VERSION "dbc-export 1 2026.26.6.5"

NS_ :

BS_:

BU_: BMS CC CP EPBR GTW HVP ICR PCS VCBATT1 VCFRONT VCLEFT VCRIGHT VCSEC

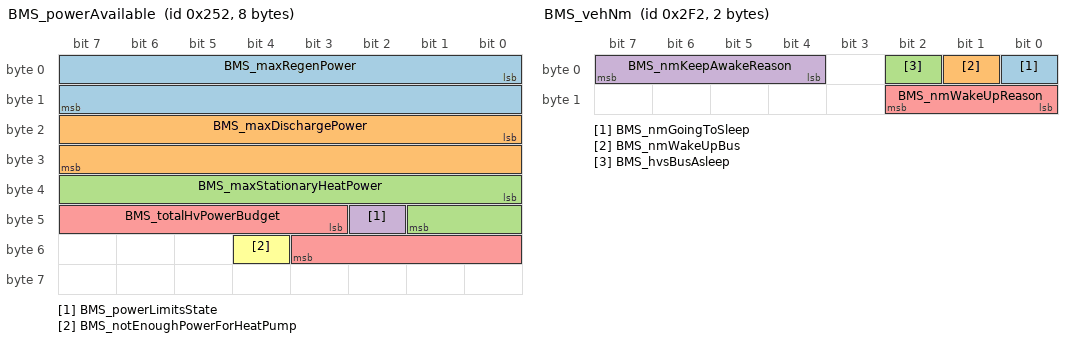
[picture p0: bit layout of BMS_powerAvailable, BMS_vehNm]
BO_ 594 BMS_powerAvailable: 8 BMS
 SG_ BMS_maxRegenPower : 0|16@1+ (0.01,0) [0|655.35] "kW" Vector__XXX
 SG_ BMS_maxDischargePower : 16|16@1+ (0.013,0) [0|850] "kW" Vector__XXX
 SG_ BMS_maxStationaryHeatPower : 32|10@1+ (0.01,0) [0|10.23] "kW" Vector__XXX
 SG_ BMS_powerLimitsState : 42|1@1+ (1,0) [0|1] "" Vector__XXX
 SG_ BMS_totalHvPowerBudget : 43|9@1+ (0.1,0) [0|51.1] "kW" Vector__XXX
 SG_ BMS_notEnoughPowerForHeatPump : 52|1@1+ (1,0) [0|1] "" Vector__XXX

BO_ 754 BMS_vehNm: 2 BMS
 SG_ BMS_nmGoingToSleep : 0|1@1+ (1,0) [0|1] "" Vector__XXX
 SG_ BMS_nmWakeUpBus : 1|1@1+ (1,0) [0|1] "" Vector__XXX
 SG_ BMS_hvsBusAsleep : 2|1@1+ (1,0) [0|1] "" Vector__XXX
 SG_ BMS_nmKeepAwakeReason : 4|4@1+ (1,0) [1|15] "" Vector__XXX
 SG_ BMS_nmWakeUpReason : 8|3@1+ (1,0) [0|7] "" Vector__XXX

BO_ 812 CC_logData: 8 CC
 SG_ CC_logIndex M : 0|8@1+ (1,0) [0|255] "" Vector__XXX
 SG_ CC_activeConnectorID m0 : 8|8@1+ (1,0) [0|255] "" Vector__XXX
 SG_ CC_temperature1 m0 : 16|8@1- (1,88) [-40|215] "DegC" Vector__XXX
 SG_ CC_temperature2 m0 : 24|8@1- (1,88) [-40|215] "DegC" Vector__XXX
 SG_ CC_temperature3 m0 : 32|8@1- (1,88) [-40|215] "DegC" Vector__XXX
 SG_ CC_contactor1Closed m0 : 40|2@1+ (1,0) [0|3] "" Vector__XXX
 SG_ CC_contactor2Closed m0 : 42|2@1+ (1,0) [0|3] "" Vector__XXX
 SG_ CC_temperature4 m0 : 44|8@1- (1,88) [-40|215] "DegC" Vector__XXX
 SG_ CC_conn1Current m1 : 8|8@1+ (0.5,0) [0|127] "A" Vector__XXX
 SG_ CC_conn2Current m2 : 8|8@1+ (0.5,0) [0|127] "A" Vector__XXX
 SG_ CC_conn3Current m3 : 8|8@1+ (0.5,0) [0|127] "A" Vector__XXX
 SG_ CC_conn4Current m4 : 8|8@1+ (0.5,0) [0|127] "A" Vector__XXX
 SG_ CC_lifetimei2t m10 : 32|32@1+ (0.1,0) [0|429496729.5] "A2h" Vector__XXX
 SG_ CC_lifetimeCtrCycles m11 : 8|28@1+ (1,0) [0|268435455] "" Vector__XXX
 SG_ CC_lifetimeCtrCyclesLoaded m11 : 36|28@1+ (1,0) [0|268435455] "" Vector__XXX
 SG_ CC_lifetimeAlertCount m12 : 8|28@1+ (1,0) [0|268435455] "" Vector__XXX
 SG_ CC_lifetimeThermalFoldbacks m12 : 36|28@1+ (1,0) [0|268435455] "" Vector__XXX
 SG_ CC_lifetimeAvgStartupTemp m13 : 36|28@1- (0.1,0) [-13421772.8|13421772.7] "degC" Vector__XXX

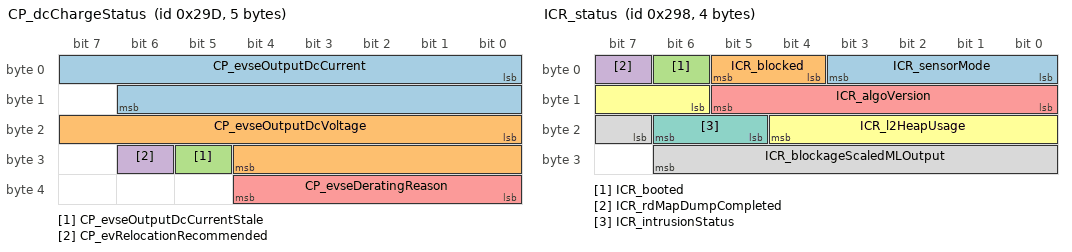
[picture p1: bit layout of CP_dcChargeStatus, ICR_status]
BO_ 669 CP_dcChargeStatus: 5 CP
 SG_ CP_evseOutputDcCurrent : 0|15@1- (0.125,0) [-2048|2047.875] "A" Vector__XXX
 SG_ CP_evseOutputDcVoltage : 16|13@1+ (0.07324219,0) [0|599.92675822] "V" Vector__XXX
 SG_ CP_evseOutputDcCurrentStale : 29|1@1+ (1,0) [0|1] "" Vector__XXX
 SG_ CP_evRelocationRecommended : 30|1@1+ (1,0) [0|1] "" Vector__XXX
 SG_ CP_evseDeratingReason : 32|5@1+ (1,0) [0|31] "" Vector__XXX

BO_ 1885 CP_loggingFast: 8 CP
 SG_ CP_loggingFastSelect M : 0|4@1+ (1,0) [0|15] "" Vector__XXX
 SG_ CP_inductiveSensor_raw m0 : 4|28@1+ (1,0) [0|268435455] "" Vector__XXX
 SG_ CP_doorOpenActuationTime m0 : 32|14@1+ (1,0) [0|16383] "ms" Vector__XXX
 SG_ CP_doorCloseActuationTime m0 : 46|14@1+ (1,0) [0|16383] "ms" Vector__XXX
 SG_ CP_chargeCableSecured m0 : 60|1@1+ (1,0) [0|1] "" Vector__XXX
 SG_ CP_chargeCablePresent m0 : 61|1@1+ (1,0) [0|1] "" Vector__XXX
 SG_ CP_latchCheckAvailable m0 : 62|1@1+ (1,0) [0|1] "" Vector__XXX
 SG_ CP_UHF_controlState m2 : 4|4@1+ (1,0) [0|15] "" Vector__XXX
 SG_ CP_proximityV m2 : 8|16@1+ (0.0001,0) [0|6.5535] "V" Vector__XXX
 SG_ CP_proximityV_GBCC1 m2 : 24|14@1+ (0.001,0) [0|13.3] "V" Vector__XXX
 SG_ CP_proximityV_GBCC2 m2 : 38|14@1+ (0.001,0) [0|13.3] "V" Vector__XXX
 SG_ CP_doorPot m2 : 52|12@1+ (0.025,0) [0|100] "%" Vector__XXX
 SG_ CP_doorPresenceSensorV m3 : 4|12@1+ (0.001221,0) [0|4.999995] "V" Vector__XXX
 SG_ CP_doorOpenRequest m3 : 16|4@1+ (1,0) [0|15] "" Vector__XXX
 SG_ CP_doorOpenEndOfDriveReason m3 : 20|3@1+ (1,0) [0|7] "" Vector__XXX
 SG_ CP_coverClosed m3 : 23|1@1+ (1,0) [0|1] "" Vector__XXX
 SG_ CP_doorCloseEndOfDriveReason m3 : 24|3@1+ (1,0) [0|7] "" Vector__XXX
 SG_ CP_doorCloseRequest m3 : 27|5@1+ (1,0) [0|31] "" Vector__XXX
 SG_ CP_latchDisengagingTime m3 : 32|10@1+ (1,0) [0|1023] "ms" Vector__XXX
 SG_ CP_latchEngagingTime m3 : 42|10@1+ (1,0) [0|1023] "ms" Vector__XXX
 SG_ CP_latchDisengagingStopReason m3 : 52|3@1+ (1,0) [0|7] "" Vector__XXX
 SG_ CP_latchEngagingStopReason m3 : 55|3@1+ (1,0) [0|7] "" Vector__XXX
 SG_ CP_pilotUnlatchRequestActive m3 : 58|1@1+ (1,0) [0|1] "" Vector__XXX
 SG_ CP_doorIdDetectionState m3 : 59|2@1+ (1,0) [1|3] "" Vector__XXX
 SG_ CP_doorIdDetectedBin m3 : 61|2@1+ (1,0) [0|3] "" Vector__XXX
 SG_ CP_semiV2LatchNonLinear m3 : 63|1@1+ (1,0) [0|1] "" Vector__XXX

BO_ 989 CP_loggingSlow: 8 CP
 SG_ CP_loggingSlowSelect M : 0|4@1+ (1,0) [0|15] "" Vector__XXX
 SG_ CP_UHF_chipState m3 : 4|3@1+ (1,0) [0|7] "" Vector__XXX
 SG_ CP_UHF_rssi m3 : 8|8@1+ (1,0) [0|255] "" Vector__XXX
 SG_ CP_UHF_rxOverflow m3 : 16|1@1+ (1,0) [0|1] "" Vector__XXX
 SG_ CP_UHF_rxNumBytes m3 : 17|8@1+ (1,0) [0|255] "" Vector__XXX
 SG_ CP_UHF_selfTestRssi m3 : 25|8@1+ (1,0) [0|255] "" Vector__XXX
 SG_ CP_latchI m3 : 33|12@1+ (0.0025,0) [0|10.2375] "A" Vector__XXX
 SG_ CP_inlet1HarnessIdState m3 : 45|2@1+ (1,0) [1|3] "" Vector__XXX
 SG_ CP_inlet1HarnessIdValue m3 : 47|3@1+ (1,0) [0|7] "" Vector__XXX
 SG_ CP_inlet2HarnessIdState m3 : 50|2@1+ (1,0) [1|3] "" Vector__XXX
 SG_ CP_inlet2HarnessIdValue m3 : 52|3@1+ (1,0) [0|7] "" Vector__XXX
 SG_ CP_inletHeaterState m3 : 55|2@1+ (1,0) [0|3] "" Vector__XXX
 SG_ CP_inletHeaterDuty m3 : 57|7@1+ (1,0) [0|100] "%" Vector__XXX
 SG_ CP_5vSwV m4 : 4|8@1+ (0.02745098,0) [0|6.9999999] "V" Vector__XXX
 SG_ CP_boardTemperature m4 : 12|8@1+ (1.29411768913,-50) [-50|280] "C" Vector__XXX
 SG_ CP_refVoltage m4 : 20|8@1+ (0.0070588234812,0) [0|1.79999998771] "V" Vector__XXX
 SG_ CP_doorId_intervalMin10s m4 : 28|8@1+ (0.0196078438312,0) [0|5] "V" Vector__XXX
 SG_ CP_doorId_intervalMax10s m4 : 36|8@1+ (0.0196078438312,0) [0|5] "V" Vector__XXX
 SG_ CP_wakeOnPushCounter m4 : 60|3@1+ (1,0) [0|7] "" Vector__XXX
 SG_ CP_doorPushLockoutActive m4 : 63|1@1+ (1,0) [0|1] "" Vector__XXX
 SG_ CP_nvm_dataValid m5 : 4|1@1+ (1,0) [0|1] "" Vector__XXX
 SG_ CP_nvm_doorOpenCycles m5 : 5|16@1+ (1,0) [0|65535] "" Vector__XXX
 SG_ CP_nvm_doorCloseCycles m5 : 21|16@1+ (1,0) [0|65535] "" Vector__XXX
 SG_ CP_nvm_doorOpen m5 : 37|1@1+ (1,0) [0|1] "" Vector__XXX
 SG_ CP_nvm_doorPresent m5 : 38|1@1+ (1,0) [0|1] "" Vector__XXX
 SG_ CP_nvm_doorPresentValid m5 : 39|1@1+ (1,0) [0|1] "" Vector__XXX
 SG_ CP_nvm_badPilotDiodeDetected m5 : 40|1@1+ (1,0) [0|1] "" Vector__XXX
 SG_ CP_nvm_pilotDiodeFaultCount m5 : 41|3@1+ (1,0) [0|7] "" Vector__XXX
 SG_ CP_doorOpenLimiterMaxCount m5 : 44|4@1+ (1,0) [0|15] "counts" Vector__XXX
 SG_ CP_doorOpenLimiterMaxRequestType m5 : 48|4@1+ (1,0) [0|15] "" Vector__XXX
 SG_ CP_doorCloseLimiterMaxCount m5 : 52|4@1+ (1,0) [0|15] "counts" Vector__XXX
 SG_ CP_doorCloseLimiterMaxRequestTyp m5 : 56|5@1+ (1,0) [0|31] "" Vector__XXX
 SG_ CP_proximityWakeCounter m5 : 61|3@1+ (1,0) [0|7] "" Vector__XXX

BO_ 893 CP_thermalStatus: 8 CP
 SG_ CP_thermalStatusSelect M : 0|1@1+ (1,0) [0|1] "" Vector__XXX
 SG_ CP_pinTemperature1 m1 : 8|8@1+ (0.8039216,-55) [-55|149.99] "C" Vector__XXX
 SG_ CP_pinTemperature2 m1 : 16|8@1+ (0.8039216,-55) [-55|149.99] "C" Vector__XXX
 SG_ CP_pinTemperature3 m1 : 24|8@1+ (0.8039216,-55) [-55|149.99] "C" Vector__XXX
 SG_ CP_pinTemperature4 m1 : 32|8@1+ (0.8039216,-55) [-55|149.99] "C" Vector__XXX
 SG_ CP_pinTemp4Velocity m1 : 40|10@1- (0.15748,0) [-80.47228|80.3148] "C/min" Vector__XXX

BO_ 2024 EPBR_info: 8 EPBR
 SG_ EPBR_infoIndex M : 0|8@1+ (1,0) [0|255] "" Vector__XXX
 SG_ EPBR_infoBuildType m10 : 8|3@1+ (1,0) [0|7] "" Vector__XXX
 SG_ EPBR_infoBuildConfigId m10 : 16|16@1+ (1,0) [0|65535] "" Vector__XXX
 SG_ EPBR_infoHardwareId m10 : 32|16@1+ (1,0) [0|65535] "" Vector__XXX
 SG_ EPBR_infoComponentId m10 : 48|16@1+ (1,0) [0|65535] "" Vector__XXX
 SG_ EPBR_infoPcbaId m11 : 8|8@1+ (1,0) [0|255] "" Vector__XXX
 SG_ EPBR_infoAssemblyId m11 : 16|8@1+ (1,0) [0|254] "" Vector__XXX
 SG_ EPBR_infoUsageId m11 : 24|16@1+ (1,0) [0|65535] "" Vector__XXX
 SG_ EPBR_infoSubUsageId m11 : 40|16@1+ (1,0) [0|65535] "" Vector__XXX
 SG_ EPBR_infoAppCrc m13 : 8|32@1+ (1,0) [0|4294967295] "" Vector__XXX
 SG_ EPBR_infoAppGitHash m17 : 8|56@1+ (1,0) [0|7.20575940379e+16] "" Vector__XXX
 SG_ EPBR_infoBootGitHash m18 : 8|56@1+ (1,0) [0|7.20575940379e+16] "" Vector__XXX
 SG_ EPBR_infoPlatformType m19 : 8|8@1+ (1,0) [0|255] "" Vector__XXX
 SG_ EPBR_infoBootUdsProtoVersion m20 : 8|16@1+ (1,0) [0|65535] "" Vector__XXX
 SG_ EPBR_infoBootCrc m20 : 24|32@1+ (1,0) [0|4294967295] "" Vector__XXX

BO_ 1914 HVP_log1hz: 8 HVP
 SG_ HVP_log1HzIndex M : 0|3@1+ (1,0) [0|7] "" Vector__XXX
 SG_ HVP_bmbAsicType m0 : 3|2@1+ (1,0) [0|3] "" Vector__XXX
 SG_ HVP_shuntCurrentAuxLog m0 : 8|24@1- (0.001,0) [-8388.607|8388.607] "A" Vector__XXX
 SG_ HVP_pyroSquibResistance m0 : 32|16@1+ (0.001,0) [0|65.534] "Ohm" Vector__XXX
 SG_ HVP_shuntAsicChipXCoordinate m0 : 48|8@1+ (1,0) [0|255] "" Vector__XXX
 SG_ HVP_shuntAsicChipYCoordinate m0 : 56|8@1+ (1,0) [0|255] "" Vector__XXX
 SG_ HVP_hvilCalType m1 : 3|2@1+ (1,0) [0|3] "" Vector__XXX
 SG_ HVP_gpioPcsDcdcPwmEnable m1 : 5|1@1+ (1,0) [0|1] "" Vector__XXX
 SG_ HVP_gpioPcsChargePwmEnable m1 : 6|1@1+ (1,0) [0|1] "" Vector__XXX
 SG_ HVP_gpioPcsEnable m1 : 7|1@1+ (1,0) [0|1] "" Vector__XXX
 SG_ HVP_shuntAsicChipWaferNumber m1 : 8|8@1+ (1,0) [0|255] "" Vector__XXX
 SG_ HVP_energyReserveMin m1 : 16|16@1- (0.001,0) [-32.768|32.767] "V" Vector__XXX
 SG_ HVP_energyReserveMax m1 : 32|16@1- (0.001,0) [-32.768|32.767] "V" Vector__XXX
 SG_ HVP_energyReserveAvg m1 : 48|16@1- (0.001,0) [-32.768|32.767] "V" Vector__XXX

BO_ 664 ICR_status: 4 ICR
 SG_ ICR_sensorMode : 0|4@1+ (1,0) [0|15] "" Vector__XXX
 SG_ ICR_blocked : 4|2@1+ (1,0) [1|3] "" Vector__XXX
 SG_ ICR_booted : 6|1@1+ (1,0) [0|1] "" Vector__XXX
 SG_ ICR_rdMapDumpCompleted : 7|1@1+ (1,0) [0|1] "" Vector__XXX
 SG_ ICR_algoVersion : 8|6@1+ (1,0) [0|63] "" Vector__XXX
 SG_ ICR_l2HeapUsage : 14|7@1+ (1,0) [0|127] "PCT" Vector__XXX
 SG_ ICR_intrusionStatus : 21|2@1+ (1,0) [0|3] "" Vector__XXX
 SG_ ICR_blockageScaledMLOutput : 23|8@1+ (0.004,0) [0|1.02] "points" Vector__XXX

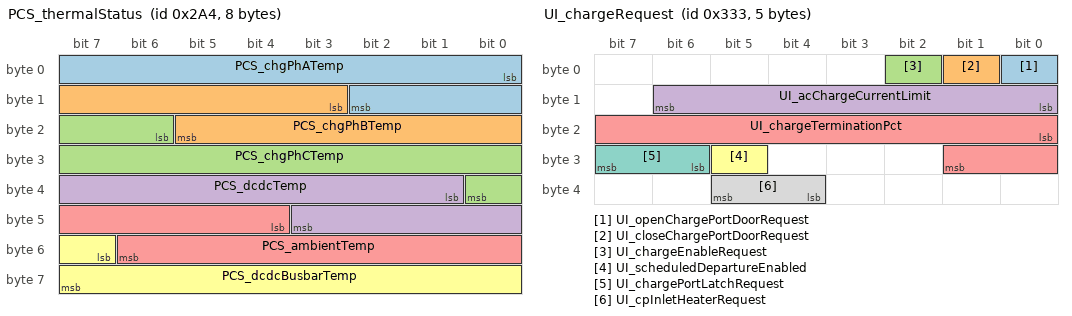
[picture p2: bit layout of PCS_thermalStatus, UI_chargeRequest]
BO_ 676 PCS_thermalStatus: 8 PCS
 SG_ PCS_chgPhATemp : 0|11@1- (0.1,40) [-62.4|142.3] "C" Vector__XXX
 SG_ PCS_chgPhBTemp : 11|11@1- (0.1,40) [-62.4|142.3] "C" Vector__XXX
 SG_ PCS_chgPhCTemp : 22|11@1- (0.1,40) [-62.4|142.3] "C" Vector__XXX
 SG_ PCS_dcdcTemp : 33|11@1- (0.1,40) [-62.4|142.3] "C" Vector__XXX
 SG_ PCS_ambientTemp : 44|11@1- (0.1,40) [-62.4|142.3] "C" Vector__XXX
 SG_ PCS_dcdcBusbarTemp : 55|9@1+ (0.2935421,0) [0|149.706471] "C" Vector__XXX

BO_ 819 UI_chargeRequest: 5 GTW
 SG_ UI_openChargePortDoorRequest : 0|1@1+ (1,0) [0|1] "" Vector__XXX
 SG_ UI_closeChargePortDoorRequest : 1|1@1+ (1,0) [0|1] "" Vector__XXX
 SG_ UI_chargeEnableRequest : 2|1@1+ (1,0) [0|1] "" Vector__XXX
 SG_ UI_acChargeCurrentLimit : 8|7@1+ (1,0) [0|126] "A" Vector__XXX
 SG_ UI_chargeTerminationPct : 16|10@1+ (0.1,0) [5|100] "%" Vector__XXX
 SG_ UI_scheduledDepartureEnabled : 29|1@1+ (1,0) [0|1] "" Vector__XXX
 SG_ UI_chargePortLatchRequest : 30|2@1+ (1,0) [0|3] "" Vector__XXX
 SG_ UI_cpInletHeaterRequest : 36|2@1+ (1,0) [0|3] "" Vector__XXX

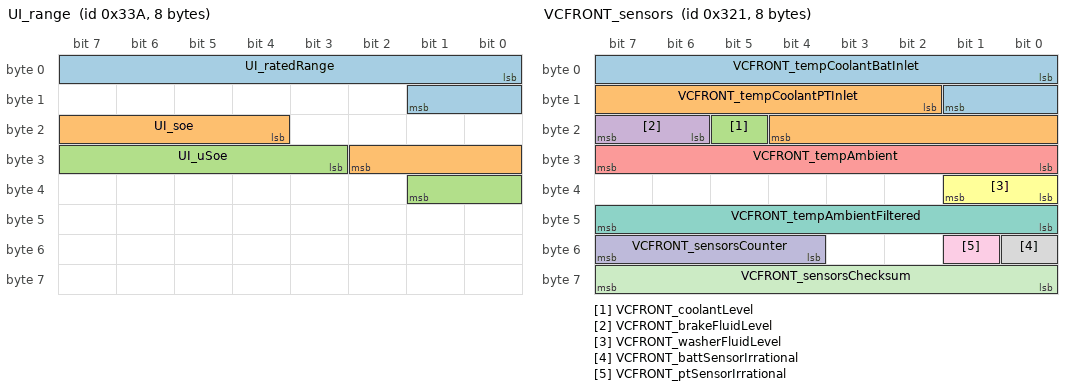
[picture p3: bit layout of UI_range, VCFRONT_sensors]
BO_ 826 UI_range: 8 GTW
 SG_ UI_ratedRange : 0|10@1+ (1,0) [0|1023] "mi" Vector__XXX
 SG_ UI_soe : 20|7@1+ (1,0) [0|127] "%" Vector__XXX
 SG_ UI_uSoe : 27|7@1+ (1,0) [0|127] "%" Vector__XXX

BO_ 1119 VCBATT1_LVSelfTests: 8 VCBATT1
 SG_ VCBATT1_LVSelfTestsChecksum : 0|8@1+ (1,0) [0|255] "" Vector__XXX
 SG_ VCBATT1_LVSelfTestsCounter : 8|4@1+ (1,0) [0|15] "" Vector__XXX
 SG_ VCBATT1_LVSelfTestsIndex M : 12|1@1+ (1,0) [0|1] "" Vector__XXX
 SG_ VCBATT1_lvProtectionSelfTestsEna m1 : 13|1@1+ (1,0) [0|1] "" Vector__XXX
 SG_ VCBATT1_startBattDomainOvercurre m1 : 14|1@1+ (1,0) [0|1] "" Vector__XXX
 SG_ VCBATT1_startBattDomainOvervolta m1 : 15|1@1+ (1,0) [0|1] "" Vector__XXX
 SG_ VCBATT1_startBattDomainUndervolt m1 : 16|1@1+ (1,0) [0|1] "" Vector__XXX
 SG_ VCBATT1_startDualPowerLoadsSelfT m1 : 17|1@1+ (1,0) [0|1] "" Vector__XXX
 SG_ VCBATT1_startVCBattBridgeEFuseAS m1 : 18|1@1+ (1,0) [0|1] "" Vector__XXX
 SG_ VCBATT1_startPCSOVShutdownSelfTe m1 : 19|1@1+ (1,0) [0|1] "" Vector__XXX
 SG_ VCBATT1_startPCSDomainOvervoltag m1 : 20|1@1+ (1,0) [0|1] "" Vector__XXX
 SG_ VCBATT1_startBattDomainUnde_0001 m1 : 21|1@1+ (1,0) [0|1] "" Vector__XXX
 SG_ VCBATT1_startPCSDomainUndervolta m1 : 22|1@1+ (1,0) [0|1] "" Vector__XXX
 SG_ VCBATT1_startVCFrontBridgeEFuseA m1 : 23|1@1+ (1,0) [0|1] "" Vector__XXX
 SG_ VCBATT1_battDomainOvercurrentSel m1 : 24|2@1+ (1,0) [0|3] "" Vector__XXX
 SG_ VCBATT1_battDomainOvercurre_0001 m1 : 26|3@1+ (1,0) [0|7] "" Vector__XXX
 SG_ VCBATT1_battDomainOvervoltageSel m1 : 29|2@1+ (1,0) [0|3] "" Vector__XXX
 SG_ VCBATT1_battDomainOvervolta_0001 m1 : 32|3@1+ (1,0) [0|7] "" Vector__XXX
 SG_ VCBATT1_battDomainUndervoltageSe m1 : 35|2@1+ (1,0) [0|3] "" Vector__XXX
 SG_ VCBATT1_battDomainUndervolt_0001 m1 : 37|3@1+ (1,0) [0|7] "" Vector__XXX
 SG_ VCBATT1_dualPowerLoadsSelfTestRe m1 : 40|2@1+ (1,0) [0|3] "" Vector__XXX
 SG_ VCBATT1_dualPowerLoadsSelfTestSt m1 : 42|3@1+ (1,0) [0|7] "" Vector__XXX
 SG_ VCBATT1_vcbattBridgeEFuseASICSel m1 : 45|2@1+ (1,0) [0|3] "" Vector__XXX
 SG_ VCBATT1_vcbattBridgeEFuseAS_0001 m1 : 48|3@1+ (1,0) [0|7] "" Vector__XXX
 SG_ VCBATT1_uvProtectionState m1 : 51|4@1+ (1,0) [0|15] "" Vector__XXX
 SG_ VCBATT1_undervoltageSelfTestFaul m1 : 55|1@1+ (1,0) [0|1] "" Vector__XXX
 SG_ VC_selfTestsRunningMode m1 : 56|3@1+ (1,0) [0|7] "" Vector__XXX

BO_ 801 VCFRONT_sensors: 8 VCFRONT
 SG_ VCFRONT_tempCoolantBatInlet : 0|10@1+ (0.125,-40) [-40|85] "degC" Vector__XXX
 SG_ VCFRONT_tempCoolantPTInlet : 10|11@1+ (0.125,-40) [-40|200] "degC" Vector__XXX
 SG_ VCFRONT_coolantLevel : 21|1@1+ (1,0) [0|1] "" Vector__XXX
 SG_ VCFRONT_brakeFluidLevel : 22|2@1+ (1,0) [1|3] "" Vector__XXX
 SG_ VCFRONT_tempAmbient : 24|8@1+ (0.5,-40) [-39.5|80] "degC" Vector__XXX
 SG_ VCFRONT_washerFluidLevel : 32|2@1+ (1,0) [1|3] "" Vector__XXX
 SG_ VCFRONT_tempAmbientFiltered : 40|8@1+ (0.5,-40) [-39.5|80] "degC" Vector__XXX
 SG_ VCFRONT_battSensorIrrational : 48|1@1+ (1,0) [0|1] "" Vector__XXX
 SG_ VCFRONT_ptSensorIrrational : 49|1@1+ (1,0) [0|1] "" Vector__XXX
 SG_ VCFRONT_sensorsCounter : 52|4@1+ (1,0) [0|15] "" Vector__XXX
 SG_ VCFRONT_sensorsChecksum : 56|8@1+ (1,0) [0|255] "" Vector__XXX

BO_ 1349 VCFRONT_systemStatus: 8 VCFRONT
 SG_ VCFRONT_systemStatusMuxIndex M : 0|2@1+ (1,0) [0|3] "" Vector__XXX
 SG_ VCFRONT_systemStatusCounter : 52|4@1+ (1,0) [0|15] "" Vector__XXX
 SG_ VCFRONT_systemStatusChecksum : 56|8@1+ (1,0) [0|255] "" Vector__XXX
 SG_ VCFRONT_loadShedReason m1 : 3|9@1+ (1,0) [0|511] "" Vector__XXX
 SG_ VCFRONT_VCRightEFuseLoadShedStag m1 : 12|5@1+ (1,0) [0|31] "" Vector__XXX
 SG_ VCFRONT_VCLeftEFuseLoadShedStage m1 : 20|5@1+ (1,0) [0|31] "" Vector__XXX
 SG_ VCFRONT_DCDCSaturationLoadShedSt m1 : 28|5@1+ (1,0) [0|31] "" Vector__XXX
 SG_ VCFRONT_vehicleLoadShedStage m1 : 36|2@1+ (1,0) [0|3] "" Vector__XXX
 SG_ VCFRONT_HVFaultVehicleLoadShedRe m1 : 38|1@1+ (1,0) [0|1] "" Vector__XXX
 SG_ VCFRONT_postCrashVehicleLoadShed m1 : 39|1@1+ (1,0) [0|1] "" Vector__XXX
 SG_ VCFRONT_HVFaultVehicleLoadShedAc m1 : 40|1@1+ (1,0) [0|1] "" Vector__XXX
 SG_ VCFRONT_factoryVehicleLoadShedAc m1 : 41|1@1+ (1,0) [0|1] "" Vector__XXX
 SG_ VCFRONT_anyVehicleLoadShedActive m1 : 42|1@1+ (1,0) [0|1] "" Vector__XXX
 SG_ VCFRONT_DIVehLoadShedActive m1 : 43|1@1+ (1,0) [0|1] "" Vector__XXX
 SG_ VCFRONT_HVFaultLoadShedStateDBG m1 : 44|2@1+ (1,0) [0|3] "" Vector__XXX
 SG_ VCFRONT_LVUnhealthyVehicleLoadSh m1 : 46|1@1+ (1,0) [0|1] "" Vector__XXX
 SG_ VCFRONT_loadShedStsCondenserFan m2 : 3|1@1+ (1,0) [0|1] "" Vector__XXX
 SG_ VCFRONT_loadShedStsPTPump m2 : 6|1@1+ (1,0) [0|1] "" Vector__XXX
 SG_ VCFRONT_loadShedMCUAudio m2 : 10|1@1+ (1,0) [0|1] "" Vector__XXX
 SG_ VCFRONT_loadShedHVDownTriggerDBG m2 : 11|1@1+ (1,0) [0|1] "" Vector__XXX
 SG_ VCFRONT_loadShedPCSSatTriggerDBG m2 : 12|1@1+ (1,0) [0|1] "" Vector__XXX
 SG_ VCFRONT_loadShedStsBatteryPump m2 : 13|1@1+ (1,0) [0|1] "" Vector__XXX
 SG_ VCFRONT_loadShedStsAPGlassHeater m2 : 14|1@1+ (1,0) [0|1] "" Vector__XXX
 SG_ VCFRONT_loadShedStsMCUGraphics m2 : 15|1@1+ (1,0) [0|1] "" Vector__XXX
 SG_ VCFRONT_IBSCurrentRMS_loadShed m2 : 16|7@1+ (0.05,0) [0|6.35] "A" Vector__XXX
 SG_ VCFRONT_loadShedAhLeakyBktCntDBG m2 : 23|9@1+ (0.001,0) [0|0.511] "Ah" Vector__XXX
 SG_ VCFRONT_loadShedPcs m2 : 33|1@1+ (1,0) [0|1] "" Vector__XXX
 SG_ VCFRONT_loadShedGTWDownstrmRails m2 : 35|1@1+ (1,0) [0|1] "" Vector__XXX
 SG_ VCFRONT_loadShedPCSMIATriggerDBG m2 : 36|1@1+ (1,0) [0|1] "" Vector__XXX
 SG_ VCFRONT_loadShedTAS m2 : 37|1@1+ (1,0) [0|1] "" Vector__XXX
 SG_ VCFRONT_loadShedBackStopBktCntDB m2 : 38|5@1+ (0.05,0) [0|1.55] "Ah" Vector__XXX
 SG_ VCFRONT_loadShedPCSLeakyBktCtDBG m2 : 44|6@1+ (100,0) [0|6300] "mV" Vector__XXX
 SG_ VCFRONT_loadShedUI m2 : 50|1@1+ (1,0) [0|1] "" Vector__XXX
 SG_ VCFRONT_loadShedAutoPilot m2 : 51|1@1+ (1,0) [0|1] "" Vector__XXX

BO_ 929 VCFRONT_vehicleStatus: 8 VCFRONT
 SG_ VCFRONT_vehicleStatusMuxIndex M : 0|1@1+ (1,0) [0|1] "" Vector__XXX
 SG_ VCFRONT_vehicleStatusCounter : 52|4@1+ (1,0) [0|15] "" Vector__XXX
 SG_ VCFRONT_vehicleStatusChecksum : 56|8@1+ (1,0) [0|255] "" Vector__XXX
 SG_ VCFRONT_preconditionRequest m0 : 1|1@1+ (1,0) [0|1] "" Vector__XXX
 SG_ VCFRONT_APGlassHeaterState m0 : 2|3@1+ (1,0) [1|7] "" Vector__XXX
 SG_ VCFRONT_thermalSystemType m0 : 5|1@1+ (1,0) [0|1] "" Vector__XXX
 SG_ VCFRONT_standbySupplySupported m0 : 6|1@1+ (1,0) [0|1] "" Vector__XXX
 SG_ VCFRONT_driverPresent m0 : 7|1@1+ (1,0) [0|1] "" Vector__XXX
 SG_ VCFRONT_passengerPresent m0 : 8|1@1+ (1,0) [0|1] "" Vector__XXX
 SG_ VCFRONT_accPlusAvailable m0 : 9|1@1+ (1,0) [0|1] "" Vector__XXX
 SG_ VCFRONT_diPowerOnState m0 : 10|3@1+ (1,0) [0|7] "" Vector__XXX
 SG_ VCFRONT_12vStatusForDrive m0 : 14|2@1+ (1,0) [0|3] "" Vector__XXX
 SG_ VCFRONT_dcr12VMilliOhms m0 : 16|8@1+ (1,0) [0|255] "mOhm" Vector__XXX
 SG_ VC_userPresenceState m0 : 24|2@1+ (1,0) [0|3] "" Vector__XXX
 SG_ VCFRONT_factoryLimitsOverrideOk m0 : 27|1@1+ (1,0) [0|1] "" Vector__XXX
 SG_ VCFRONT_ota12VSupportRequest m0 : 29|1@1+ (1,0) [0|1] "" Vector__XXX
 SG_ VCFRONT_driverBuckleStatus m0 : 30|1@1+ (1,0) [0|1] "" Vector__XXX
 SG_ VCFRONT_driverDoorStatus m0 : 31|1@1+ (1,0) [0|1] "" Vector__XXX
 SG_ VCFRONT_driverUnbuckled m0 : 32|2@1+ (1,0) [0|3] "" Vector__XXX
 SG_ VCFRONT_passengerUnbuckled m0 : 34|2@1+ (1,0) [0|3] "" Vector__XXX
 SG_ VCFRONT_2RowLeftUnbuckled m0 : 36|2@1+ (1,0) [0|3] "" Vector__XXX
 SG_ VCFRONT_2RowCenterUnbuckled m0 : 38|2@1+ (1,0) [0|3] "" Vector__XXX
 SG_ VCFRONT_2RowRightUnbuckled m0 : 40|2@1+ (1,0) [0|3] "" Vector__XXX
 SG_ VCFRONT_pcsEFuseVoltage m0 : 42|10@1+ (0.1,0) [0|102.2] "V" Vector__XXX
 SG_ VCFRONT_bmsHvChargeEnable m1 : 1|1@1+ (1,0) [0|1] "" Vector__XXX
 SG_ VCFRONT_3RowLeftUnbuckled m1 : 2|2@1+ (1,0) [0|3] "" Vector__XXX
 SG_ VCFRONT_3RowRightUnbuckled m1 : 4|2@1+ (1,0) [0|3] "" Vector__XXX
 SG_ VCFRONT_maxBattHeatRejection m1 : 6|10@1+ (30,0) [0|30690] "W" Vector__XXX
 SG_ VCFRONT_hvacReqBattCoolOutTemp m1 : 16|9@1+ (0.1,40) [40|91.1] "degC" Vector__XXX
 SG_ VCFRONT_PCSCurrent m1 : 25|13@1- (0.1,0) [-409.6|409.5] "A" Vector__XXX
 SG_ VCFRONT_refSystemNominal m1 : 38|1@1+ (1,0) [0|1] "" Vector__XXX
 SG_ VCFRONT_driverEnteredCabinEstima m1 : 39|1@1+ (1,0) [0|1] "" Vector__XXX
 SG_ VCFRONT_anySWEFuseActive m1 : 40|1@1+ (1,0) [0|1] "" Vector__XXX
 SG_ VCFRONT_hpBattHeatingPowerTrgt m1 : 41|7@1+ (100,0) [0|10000] "W" Vector__XXX

BO_ 258 VCLEFT_doorStatus: 8 VCLEFT
 SG_ VCLEFT_doorClosureStatusFront : 0|4@1+ (1,0) [1|15] "" Vector__XXX
 SG_ VCLEFT_doorClosureStatusRear : 4|4@1+ (1,0) [1|15] "" Vector__XXX
 SG_ VCLEFT_frontLatchSwitch : 8|1@1+ (1,0) [0|1] "" Vector__XXX
 SG_ VCLEFT_rearLatchSwitch : 9|1@1+ (1,0) [0|1] "" Vector__XXX
 SG_ VCLEFT_frontHandlePulled : 10|1@1+ (1,0) [0|1] "" Vector__XXX
 SG_ VCLEFT_rearHandlePulled : 11|1@1+ (1,0) [0|1] "" Vector__XXX
 SG_ VCLEFT_frontRelActuatorSwitch : 12|1@1+ (1,0) [0|1] "" Vector__XXX
 SG_ VCLEFT_rearRelActuatorSwitch : 13|1@1+ (1,0) [0|1] "" Vector__XXX
 SG_ VCLEFT_frontLatchStatus : 14|4@1+ (1,0) [1|15] "" Vector__XXX
 SG_ VCLEFT_rearLatchStatus : 18|4@1+ (1,0) [1|15] "" Vector__XXX
 SG_ VCLEFT_lastDoorReqSourceFront : 22|3@1+ (1,0) [0|7] "" Vector__XXX
 SG_ VCLEFT_lastDoorReqSourceRear : 25|3@1+ (1,0) [0|7] "" Vector__XXX
 SG_ VCLEFT_frontIntSwitchFaulted : 28|1@1+ (1,0) [0|1] "" Vector__XXX
 SG_ VCLEFT_rearIntSwitchFaulted : 29|1@1+ (1,0) [0|1] "" Vector__XXX
 SG_ VCLEFT_frontIntSwitchPressed : 31|1@1+ (1,0) [0|1] "" Vector__XXX
 SG_ VCLEFT_rearIntSwitchPressed : 32|1@1+ (1,0) [0|1] "" Vector__XXX
 SG_ VCLEFT_mirrorTiltXPosition : 33|8@1+ (0.02,0) [0|5] "V" Vector__XXX
 SG_ VCLEFT_mirrorTiltYPosition : 41|8@1+ (0.02,0) [0|5] "V" Vector__XXX
 SG_ VCLEFT_mirrorState : 49|3@1+ (1,0) [0|7] "" Vector__XXX
 SG_ VCLEFT_mirrorFoldState : 52|3@1+ (1,0) [0|7] "" Vector__XXX
 SG_ VCLEFT_mirrorRecallState : 55|3@1+ (1,0) [0|7] "" Vector__XXX
 SG_ VCLEFT_mirrorHeatState : 58|3@1+ (1,0) [1|7] "" Vector__XXX
 SG_ VCLEFT_rearHandlePulledPersist : 61|1@1+ (1,0) [0|1] "" Vector__XXX
 SG_ VCLEFT_frontHandlePulledPersist : 62|1@1+ (1,0) [0|1] "" Vector__XXX
 SG_ VCLEFT_mirrorDipped : 63|1@1+ (1,0) [0|1] "" Vector__XXX

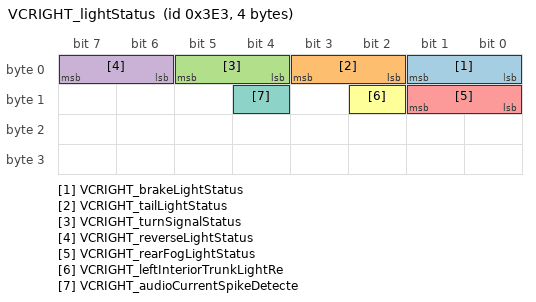
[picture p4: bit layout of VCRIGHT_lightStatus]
BO_ 995 VCRIGHT_lightStatus: 4 VCRIGHT
 SG_ VCRIGHT_brakeLightStatus : 0|2@1+ (1,0) [0|2] "" Vector__XXX
 SG_ VCRIGHT_tailLightStatus : 2|2@1+ (1,0) [0|2] "" Vector__XXX
 SG_ VCRIGHT_turnSignalStatus : 4|2@1+ (1,0) [0|2] "" Vector__XXX
 SG_ VCRIGHT_reverseLightStatus : 6|2@1+ (1,0) [0|2] "" Vector__XXX
 SG_ VCRIGHT_rearFogLightStatus : 8|2@1+ (1,0) [0|2] "" Vector__XXX
 SG_ VCRIGHT_leftInteriorTrunkLightRe : 10|1@1+ (1,0) [0|1] "" Vector__XXX
 SG_ VCRIGHT_audioCurrentSpikeDetecte : 12|1@1+ (1,0) [0|1] "" Vector__XXX

BO_ 1066 VCSEC_TPMSConnectionData: 8 VCSEC
 SG_ VCSEC_TPMSSensorState0 : 0|3@1+ (1,0) [0|7] "" Vector__XXX
 SG_ VCSEC_TPMSRSSI0 : 3|7@1+ (1,-127) [-127|0] "dBm" Vector__XXX
 SG_ VCSEC_TPMSConnectionTypeCurrent0 : 10|2@1+ (1,0) [0|3] "" Vector__XXX
 SG_ VCSEC_TPMSConnectionTypeDesired0 : 12|2@1+ (1,0) [0|3] "" Vector__XXX
 SG_ VCSEC_TPMSSensorState1 : 14|3@1+ (1,0) [0|7] "" Vector__XXX
 SG_ VCSEC_TPMSRSSI1 : 17|7@1+ (1,-127) [-127|0] "dBm" Vector__XXX
 SG_ VCSEC_TPMSConnectionTypeCurrent1 : 24|2@1+ (1,0) [0|3] "" Vector__XXX
 SG_ VCSEC_TPMSConnectionTypeDesired1 : 26|2@1+ (1,0) [0|3] "" Vector__XXX
 SG_ VCSEC_TPMSSensorState2 : 28|3@1+ (1,0) [0|7] "" Vector__XXX
 SG_ VCSEC_TPMSRSSI2 : 31|7@1+ (1,-127) [-127|0] "dBm" Vector__XXX
 SG_ VCSEC_TPMSConnectionTypeCurrent2 : 38|2@1+ (1,0) [0|3] "" Vector__XXX
 SG_ VCSEC_TPMSConnectionTypeDesired2 : 40|2@1+ (1,0) [0|3] "" Vector__XXX
 SG_ VCSEC_TPMSSensorState3 : 42|3@1+ (1,0) [0|7] "" Vector__XXX
 SG_ VCSEC_TPMSRSSI3 : 45|7@1+ (1,-127) [-127|0] "dBm" Vector__XXX
 SG_ VCSEC_TPMSConnectionTypeCurrent3 : 52|2@1+ (1,0) [0|3] "" Vector__XXX
 SG_ VCSEC_TPMSConnectionTypeDesired3 : 54|2@1+ (1,0) [0|3] "" Vector__XXX
 SG_ VCSEC_TPMSSensorPresence0 : 56|2@1+ (1,0) [0|3] "" Vector__XXX
 SG_ VCSEC_TPMSSensorPresence1 : 58|2@1+ (1,0) [0|3] "" Vector__XXX
 SG_ VCSEC_TPMSSensorPresence2 : 60|2@1+ (1,0) [0|3] "" Vector__XXX
 SG_ VCSEC_TPMSSensorPresence3 : 62|2@1+ (1,0) [0|3] "" Vector__XXX

BO_ 1817 VCSEC_debug100ms: 8 VCSEC
 SG_ VCSEC_debug100msIndex M : 0|5@1+ (1,0) [0|31] "" Vector__XXX
 SG_ VCSEC_walkAwayLockKeyState m0 : 5|2@1+ (1,0) [0|3] "" Vector__XXX
 SG_ VCSEC_thresholdOffsetVersion m0 : 8|3@1+ (1,0) [0|7] "" Vector__XXX
 SG_ VCSEC_walkAwayLockState m0 : 11|3@1+ (1,0) [0|7] "" Vector__XXX
 SG_ VCSEC_rssi0WLEntry m0 : 16|5@1+ (1,0) [0|31] "" Vector__XXX
 SG_ VCSEC_endpointLayout m0 : 21|2@1+ (1,0) [0|3] "" Vector__XXX
 SG_ VCSEC_rssi1WLEntry m0 : 24|5@1+ (1,0) [0|31] "" Vector__XXX
 SG_ VCSEC_rssi2WLEntry m0 : 32|5@1+ (1,0) [0|31] "" Vector__XXX
 SG_ VCSEC_walkUpUnlockState m0 : 37|3@1+ (1,0) [0|7] "" Vector__XXX
 SG_ VCSEC_algoHighThreshLeft m0 : 40|1@1+ (1,0) [0|1] "" Vector__XXX
 SG_ VCSEC_algoHighThreshRight m0 : 41|1@1+ (1,0) [0|1] "" Vector__XXX
 SG_ VCSEC_algoHighThreshCenter m0 : 42|1@1+ (1,0) [0|1] "" Vector__XXX
 SG_ VCSEC_pollingReason m0 : 43|4@1+ (1,0) [0|15] "" Vector__XXX
 SG_ VCSEC_numberOfPubKeysOnWhitelist m0 : 48|5@1+ (1,0) [0|31] "" Vector__XXX
 SG_ VCSEC_thermalDetectState m0 : 53|2@1+ (1,0) [0|3] "" Vector__XXX
 SG_ VCSEC_chargeHandleMitigationActi m0 : 55|1@1+ (1,0) [0|1] "" Vector__XXX
 SG_ VCSEC_device0Offset m5 : 26|6@1- (0.5,0) [-16|15.5] "dBm" Vector__XXX
 SG_ VCSEC_device1Offset m5 : 32|6@1- (0.5,0) [-16|15.5] "dBm" Vector__XXX
 SG_ VCSEC_device2Offset m5 : 40|6@1- (0.5,0) [-16|15.5] "dBm" Vector__XXX

BO_TX_BU_ 594 : BMS;
BO_TX_BU_ 754 : BMS;
BO_TX_BU_ 812 : CC;
BO_TX_BU_ 669 : CP;
BO_TX_BU_ 1885 : CP;
BO_TX_BU_ 989 : CP;
BO_TX_BU_ 893 : CP;
BO_TX_BU_ 2024 : EPBR;
BO_TX_BU_ 1914 : HVP;
BO_TX_BU_ 664 : ICR;
BO_TX_BU_ 676 : PCS;
BO_TX_BU_ 819 : GTW;
BO_TX_BU_ 826 : GTW;
BO_TX_BU_ 1119 : VCBATT1;
BO_TX_BU_ 801 : VCFRONT;
BO_TX_BU_ 1349 : VCFRONT;
BO_TX_BU_ 929 : VCFRONT;
BO_TX_BU_ 258 : VCLEFT;
BO_TX_BU_ 995 : VCRIGHT;
BO_TX_BU_ 1066 : VCSEC;
BO_TX_BU_ 1817 : VCSEC;

CM_ "Tesla Bayberry CAN bus database; bus VEH (vehicle CAN); firmware 2026.26.6.5. Decoded CAN signal definitions (layout, scaling, units, value tables).";
CM_ BU_ BMS "High-voltage battery management system";
CM_ BU_ CC "Charge cable controller";
CM_ BU_ CP "Charge port controller";
CM_ BU_ EPBR "Right electric parking brake";
CM_ BU_ GTW "Gateway";
CM_ BU_ HVP "High-voltage processor (pack contactor and isolation controller)";
CM_ BU_ ICR "ICR ECU";
CM_ BU_ PCS "Power conversion system (on-board charger and DC-DC converter)";
CM_ BU_ VCBATT1 "VCBATT1 ECU";
CM_ BU_ VCFRONT "Front body controller";
CM_ BU_ VCLEFT "Left body controller";
CM_ BU_ VCRIGHT "Right body controller";
CM_ BU_ VCSEC "Vehicle security controller";
CM_ BO_ 594 "High-voltage battery management system message: power available; frame length observed on a vehicle bus";
CM_ SG_ 594 BMS_maxRegenPower "Calculated max regen power";
CM_ SG_ 594 BMS_maxDischargePower "Calculated max discharge power possible based on max discharge current and sum of loaded voltages";
CM_ SG_ 594 BMS_maxStationaryHeatPower "Maximum heating power the DI can produce when in stationary heating mode";
CM_ SG_ 594 BMS_powerLimitsState "High-voltage battery management system: power limits state";
CM_ SG_ 594 BMS_totalHvPowerBudget "Maximum total power that the High Voltage (HV) battery and Electric Vehicle Supply Equipment (EVSE) (if present) can safely produce";
CM_ SG_ 594 BMS_notEnoughPowerForHeatPump "Flag indicating the min pack power is lower than specified threshold to support heating with the heat pump";
CM_ BO_ 754 "High-voltage battery management system message: veh nm; frame length observed on a vehicle bus";
CM_ SG_ 754 BMS_nmGoingToSleep "High-voltage battery management system: nm going to sleep";
CM_ SG_ 754 BMS_nmWakeUpBus "High-voltage battery management system: nm wake up bus";
CM_ SG_ 754 BMS_hvsBusAsleep "HVS bus reported as off";
CM_ SG_ 754 BMS_nmKeepAwakeReason "BMS' determined reason to keep CAN awake; raw 0 = signal not available (SNA)";
CM_ SG_ 754 BMS_nmWakeUpReason "BMS' determined reason to wake up CAN";
CM_ BO_ 812 "Charge cable controller message: log data; frame length from the layout, not yet observed on a vehicle bus";
CM_ SG_ 812 CC_logIndex "Charge cable controller: log index";
CM_ SG_ 812 CC_activeConnectorID "Site identifier of active charge connector";
CM_ SG_ 812 CC_temperature1 "Charge cable vehicle connector temperature";
CM_ SG_ 812 CC_temperature2 "Charge cable vehicle connector temperature";
CM_ SG_ 812 CC_temperature3 "Charge cable vehicle connector temperature";
CM_ SG_ 812 CC_contactor1Closed "State of contactor 1 in wall connector";
CM_ SG_ 812 CC_contactor2Closed "State of contactor 1 in wall connector";
CM_ SG_ 812 CC_temperature4 "Charge cable vehicle connector temperature";
CM_ SG_ 812 CC_conn1Current "AC current on connector 1 in wall charger load sharing group; raw 255 = signal not available (SNA)";
CM_ SG_ 812 CC_conn2Current "AC current on connector 2 in wall charger load sharing group; raw 255 = signal not available (SNA)";
CM_ SG_ 812 CC_conn3Current "AC current on connector 3 in wall charger load sharing group; raw 255 = signal not available (SNA)";
CM_ SG_ 812 CC_conn4Current "AC current on connector 4 in wall charger load sharing group; raw 255 = signal not available (SNA)";
CM_ SG_ 812 CC_lifetimei2t "Charge cable controller: lifetimei2t";
CM_ SG_ 812 CC_lifetimeCtrCycles "Charge cable controller: lifetime ctr cycles";
CM_ SG_ 812 CC_lifetimeCtrCyclesLoaded "Charge cable controller: lifetime ctr cycles loaded";
CM_ SG_ 812 CC_lifetimeAlertCount "Charge cable controller: lifetime alert count";
CM_ SG_ 812 CC_lifetimeThermalFoldbacks "Charge cable controller: lifetime thermal foldbacks";
CM_ SG_ 812 CC_lifetimeAvgStartupTemp "Charge cable controller: lifetime avg startup temp";
CM_ BO_ 669 "Charge port controller message: dc charge status; frame length observed on a vehicle bus";
CM_ SG_ 669 CP_evseOutputDcCurrent "The DC EVSE's measured output current";
CM_ SG_ 669 CP_evseOutputDcVoltage "The DC EVSE's measured output voltage";
CM_ SG_ 669 CP_evseOutputDcCurrentStale "Indicates whether the data in CP_evseOutputDcCurrent has not been updated with new info from the DC EVSE recently";
CM_ SG_ 669 CP_evRelocationRecommended "Indicates whether the supercharger EVSE recommends relocating the vehicle";
CM_ SG_ 669 CP_evseDeratingReason "Reports the derating reason from Supercharger EVSE";
CM_ BO_ 1885 "Charge port controller message: logging fast; frame length observed on a vehicle bus";
CM_ SG_ 1885 CP_loggingFastSelect "Charge port controller: logging fast select";
CM_ SG_ 1885 CP_inductiveSensor_raw "Charge port controller: inductive sensor raw";
CM_ SG_ 1885 CP_doorOpenActuationTime "Charge port controller: door open actuation time";
CM_ SG_ 1885 CP_doorCloseActuationTime "Charge port controller: door close actuation time";
CM_ SG_ 1885 CP_chargeCableSecured "Indicates whether a charge cable is secured in any inlet";
CM_ SG_ 1885 CP_chargeCablePresent "Indicates whether a charge cable is present in any inlet";
CM_ SG_ 1885 CP_latchCheckAvailable "Charge port controller: latch check available";
CM_ SG_ 1885 CP_UHF_controlState "Control state of UHF receiver";
CM_ SG_ 1885 CP_proximityV "Charge port controller: proximity v";
CM_ SG_ 1885 CP_proximityV_GBCC1 "Sensed voltage of GB DC inlet CC1 connection";
CM_ SG_ 1885 CP_proximityV_GBCC2 "Sensed voltage of GB DC inlet CC2 connection";
CM_ SG_ 1885 CP_doorPot "Position of the charge port door potentiometer";
CM_ SG_ 1885 CP_doorPresenceSensorV "Reports voltage value read by the charge port door's presence sensor.";
CM_ SG_ 1885 CP_doorOpenRequest "Door open request trigger";
CM_ SG_ 1885 CP_doorOpenEndOfDriveReason "Reason why the door stopped moving in the open direction";
CM_ SG_ 1885 CP_coverClosed "Charge port controller: cover closed";
CM_ SG_ 1885 CP_doorCloseEndOfDriveReason "Reason why the door stopped moving in the closing direction";
CM_ SG_ 1885 CP_doorCloseRequest "Door close request trigger";
CM_ SG_ 1885 CP_latchDisengagingTime "Charge port controller: latch disengaging time";
CM_ SG_ 1885 CP_latchEngagingTime "Charge port controller: latch engaging time";
CM_ SG_ 1885 CP_latchDisengagingStopReason "Reason why the latch stopped moving in the engaged direction";
CM_ SG_ 1885 CP_latchEngagingStopReason "Reason why the latch stopped moving in the engaged direction";
CM_ SG_ 1885 CP_pilotUnlatchRequestActive "Reports whether the Charge Port (CP) pilot unlatch request is active.";
CM_ SG_ 1885 CP_doorIdDetectionState "Charge port controller: door id detection state; raw 0 = signal not available (SNA)";
CM_ SG_ 1885 CP_doorIdDetectedBin "Charge port controller: door id detected bin";
CM_ SG_ 1885 CP_semiV2LatchNonLinear "Reports whether the Charge Port (CP) SemiV2 latch potentiometer reading is non-linear.";
CM_ BO_ 989 "Charge port controller message: logging slow; frame length observed on a vehicle bus";
CM_ SG_ 989 CP_loggingSlowSelect "Charge port controller: logging slow select";
CM_ SG_ 989 CP_UHF_chipState "Charge port controller: UHF chip state";
CM_ SG_ 989 CP_UHF_rssi "Signal strength of received UHF signal";
CM_ SG_ 989 CP_UHF_rxOverflow "Charge port controller: UHF rx overflow";
CM_ SG_ 989 CP_UHF_rxNumBytes "Charge port controller: UHF rx num bytes";
CM_ SG_ 989 CP_UHF_selfTestRssi "Signal strength of received self-test UHF signal";
CM_ SG_ 989 CP_latchI "Charge port controller: latch i";
CM_ SG_ 989 CP_inlet1HarnessIdState "State of the CP's inlet 1 harness pedigree; raw 0 = signal not available (SNA)";
CM_ SG_ 989 CP_inlet1HarnessIdValue "Pedigree of the CP's inlet 1 harness";
CM_ SG_ 989 CP_inlet2HarnessIdState "State of the CP's inlet 2 harness pedigree; raw 0 = signal not available (SNA)";
CM_ SG_ 989 CP_inlet2HarnessIdValue "Pedigree of the CP's inlet 2 harness";
CM_ SG_ 989 CP_inletHeaterState "Reports the present state of the inlet heater.";
CM_ SG_ 989 CP_inletHeaterDuty "Inlet heater PWM duty cycle";
CM_ SG_ 989 CP_5vSwV "Charge port controller: 5v sw v";
CM_ SG_ 989 CP_boardTemperature "Charge port controller: board temperature";
CM_ SG_ 989 CP_refVoltage "Charge port controller: ref voltage";
CM_ SG_ 989 CP_doorId_intervalMin10s "Charge port controller: door id interval min10s";
CM_ SG_ 989 CP_doorId_intervalMax10s "Charge port controller: door id interval max10s";
CM_ SG_ 989 CP_wakeOnPushCounter "Charge port controller: wake on push counter";
CM_ SG_ 989 CP_doorPushLockoutActive "Reports whether the Charge Port (CP) wake on press has been disabled due to rate-limiting.";
CM_ SG_ 989 CP_nvm_dataValid "Charge port controller: nvm data valid";
CM_ SG_ 989 CP_nvm_doorOpenCycles "Charge port controller: nvm door open cycles";
CM_ SG_ 989 CP_nvm_doorCloseCycles "Charge port controller: nvm door close cycles";
CM_ SG_ 989 CP_nvm_doorOpen "Charge port controller: nvm door open";
CM_ SG_ 989 CP_nvm_doorPresent "Charge port controller: nvm door present";
CM_ SG_ 989 CP_nvm_doorPresentValid "Charge port controller: nvm door present valid";
CM_ SG_ 989 CP_nvm_badPilotDiodeDetected "Charge port controller: nvm bad pilot diode detected";
CM_ SG_ 989 CP_nvm_pilotDiodeFaultCount "Charge port controller: nvm pilot diode fault count";
CM_ SG_ 989 CP_doorOpenLimiterMaxCount "Charge port controller: door open limiter max count";
CM_ SG_ 989 CP_doorOpenLimiterMaxRequestType "Charge port controller: door open limiter max request type";
CM_ SG_ 989 CP_doorCloseLimiterMaxCount "Charge port controller: door close limiter max count";
CM_ SG_ 989 CP_doorCloseLimiterMaxRequestTyp "Charge port controller: door close limiter max request type";
CM_ SG_ 989 CP_proximityWakeCounter "Charge port controller: proximity wake counter";
CM_ BO_ 893 "Charge port controller message: thermal status; frame length observed on a vehicle bus";
CM_ SG_ 893 CP_thermalStatusSelect "Charge port controller: thermal status select";
CM_ SG_ 893 CP_pinTemperature1 "Sensed temperature of the charge port inlet pins";
CM_ SG_ 893 CP_pinTemperature2 "Sensed temperature of the charge port inlet pins";
CM_ SG_ 893 CP_pinTemperature3 "Sensed temperature of the charge port inlet pins";
CM_ SG_ 893 CP_pinTemperature4 "Sensed temperature of the charge port inlet pins";
CM_ SG_ 893 CP_pinTemp4Velocity "Instantaneous temperature velocity (over 1 minute) of Charge Port's temperature 4; raw 511 = signal not available (SNA)";
CM_ BO_ 2024 "Right electric parking brake message: info; frame length observed on a vehicle bus";
CM_ SG_ 2024 EPBR_infoIndex "Right electric parking brake: info index";
CM_ SG_ 2024 EPBR_infoBuildType "Right electric parking brake: info build type";
CM_ SG_ 2024 EPBR_infoBuildConfigId "Right electric parking brake: info build config id";
CM_ SG_ 2024 EPBR_infoHardwareId "Right electric parking brake: info hardware id";
CM_ SG_ 2024 EPBR_infoComponentId "Right electric parking brake: info component id";
CM_ SG_ 2024 EPBR_infoPcbaId "Right electric parking brake: info pcba id";
CM_ SG_ 2024 EPBR_infoAssemblyId "Right electric parking brake: info assembly id; raw 255 = signal not available (SNA)";
CM_ SG_ 2024 EPBR_infoUsageId "Right electric parking brake: info usage id";
CM_ SG_ 2024 EPBR_infoSubUsageId "Right electric parking brake: info sub usage id";
CM_ SG_ 2024 EPBR_infoAppCrc "Right electric parking brake: info app crc";
CM_ SG_ 2024 EPBR_infoAppGitHash "Right electric parking brake: info app git hash";
CM_ SG_ 2024 EPBR_infoBootGitHash "Right electric parking brake: info boot git hash";
CM_ SG_ 2024 EPBR_infoPlatformType "Right electric parking brake: info platform type";
CM_ SG_ 2024 EPBR_infoBootUdsProtoVersion "Right electric parking brake: info boot uds proto version";
CM_ SG_ 2024 EPBR_infoBootCrc "Right electric parking brake: info boot crc";
CM_ BO_ 1914 "High-voltage processor (pack contactor and isolation controller) message: log1hz; frame length observed on a vehicle bus";
CM_ SG_ 1914 HVP_log1HzIndex "High-voltage processor (pack contactor and isolation controller): log1 hz index";
CM_ SG_ 1914 HVP_bmbAsicType "The BMB Asic type being used by this battery pack for reading brick data";
CM_ SG_ 1914 HVP_shuntCurrentAuxLog "High-voltage processor (pack contactor and isolation controller): shunt current aux log";
CM_ SG_ 1914 HVP_pyroSquibResistance "The pyro resistance measured on attempt to close contactor or by the Pyro selftest; raw 65535 = signal not available (SNA)";
CM_ SG_ 1914 HVP_shuntAsicChipXCoordinate "High-voltage processor (pack contactor and isolation controller): shunt asic chip x coordinate";
CM_ SG_ 1914 HVP_shuntAsicChipYCoordinate "High-voltage processor (pack contactor and isolation controller): shunt asic chip y coordinate";
CM_ SG_ 1914 HVP_hvilCalType "High-voltage processor (pack contactor and isolation controller): hvil cal type";
CM_ SG_ 1914 HVP_gpioPcsDcdcPwmEnable "High-voltage processor (pack contactor and isolation controller): gpio pcs dcdc pwm enable";
CM_ SG_ 1914 HVP_gpioPcsChargePwmEnable "High-voltage processor (pack contactor and isolation controller): gpio pcs charge pwm enable";
CM_ SG_ 1914 HVP_gpioPcsEnable "HVP GPIO control for PCS logic power enable line";
CM_ SG_ 1914 HVP_shuntAsicChipWaferNumber "High-voltage processor (pack contactor and isolation controller): shunt asic chip wafer number";
CM_ SG_ 1914 HVP_energyReserveMin "a lowest energy reserve value measured over sliding window";
CM_ SG_ 1914 HVP_energyReserveMax "a highest energy reserve value measured over sliding window";
CM_ SG_ 1914 HVP_energyReserveAvg "an average energy reserve value measured over sliding window";
CM_ BO_ 664 "ICR ECU message: status; frame length from the layout, not yet observed on a vehicle bus";
CM_ SG_ 664 ICR_sensorMode "ICR ECU: sensor mode";
CM_ SG_ 664 ICR_blocked "Indicates if sensor is blocked or not; raw 0 = signal not available (SNA)";
CM_ SG_ 664 ICR_booted "Indicates if ICR has rebooted";
CM_ SG_ 664 ICR_rdMapDumpCompleted "ICR ECU: rd map dump completed";
CM_ SG_ 664 ICR_algoVersion "ICR ECU: algo version";
CM_ SG_ 664 ICR_l2HeapUsage "ICR ECU: l2 heap usage";
CM_ SG_ 664 ICR_intrusionStatus "ICR ECU: intrusion status";
CM_ SG_ 664 ICR_blockageScaledMLOutput "Indicates a scaled blockage ML Output";
CM_ BO_ 676 "Power conversion system (on-board charger and DC-DC converter) message: thermal status; frame length observed on a vehicle bus";
CM_ SG_ 676 PCS_chgPhATemp "Sensed temperature of AC charger phase A; raw 1025 = signal not available (SNA)";
CM_ SG_ 676 PCS_chgPhBTemp "Sensed temperature of AC charger phase B; raw 1025 = signal not available (SNA)";
CM_ SG_ 676 PCS_chgPhCTemp "Sensed temperature of AC charger phase C; raw 1025 = signal not available (SNA)";
CM_ SG_ 676 PCS_dcdcTemp "Sensed temperature of DCDC; raw 1025 = signal not available (SNA)";
CM_ SG_ 676 PCS_ambientTemp "Ambient temperature sensed by the PCS; raw 1025 = signal not available (SNA)";
CM_ SG_ 676 PCS_dcdcBusbarTemp "Sensed temperature of DCDC busbar; raw 511 = signal not available (SNA)";
CM_ BO_ 819 "Touchscreen user interface computer message: charge request; forwarded onto this bus by the gateway; frame length observed on a vehicle bus";
CM_ SG_ 819 UI_openChargePortDoorRequest "Request to open charge port.";
CM_ SG_ 819 UI_closeChargePortDoorRequest "Request to close charge port.";
CM_ SG_ 819 UI_chargeEnableRequest "Charging request initiated";
CM_ SG_ 819 UI_acChargeCurrentLimit "UI charging line current request; raw 127 = signal not available (SNA)";
CM_ SG_ 819 UI_chargeTerminationPct "Charge Termination Limit Percent";
CM_ SG_ 819 UI_scheduledDepartureEnabled "Reports scheduled departure feature enablement.";
CM_ SG_ 819 UI_chargePortLatchRequest "Request to engage or disengage the latch.";
CM_ SG_ 819 UI_cpInletHeaterRequest "Enable charge port inlet heater";
CM_ BO_ 826 "Touchscreen user interface computer message: range; forwarded onto this bus by the gateway; frame length observed on a vehicle bus";
CM_ SG_ 826 UI_ratedRange "Rated range in miles";
CM_ SG_ 826 UI_soe "State of energy";
CM_ SG_ 826 UI_uSoe "Usable state of energy";
CM_ BO_ 1119 "VCBATT1 ECU message: LV self tests; frame length from the layout, not yet observed on a vehicle bus";
CM_ SG_ 1119 VCBATT1_LVSelfTestsChecksum "VCBATT1 ECU: LV self tests checksum";
CM_ SG_ 1119 VCBATT1_LVSelfTestsCounter "VCBATT1 ECU: LV self tests counter";
CM_ SG_ 1119 VCBATT1_LVSelfTestsIndex "VCBATT1 ECU: LV self tests index";
CM_ SG_ 1119 VCBATT1_lvProtectionSelfTestsEna "VCBATT1 ECU: lv protection self tests enabled";
CM_ SG_ 1119 VCBATT1_startBattDomainOvercurre "VCBATT1 ECU: start batt domain overcurrent self test";
CM_ SG_ 1119 VCBATT1_startBattDomainOvervolta "VCBATT1 ECU: start batt domain overvoltage self test";
CM_ SG_ 1119 VCBATT1_startBattDomainUndervolt "VCBATT1 ECU: start batt domain undervoltage self test";
CM_ SG_ 1119 VCBATT1_startDualPowerLoadsSelfT "VCBATT1 ECU: start dual power loads self test";
CM_ SG_ 1119 VCBATT1_startVCBattBridgeEFuseAS "VCBATT1 ECU: start VC batt bridge e fuse ASIC self test";
CM_ SG_ 1119 VCBATT1_startPCSOVShutdownSelfTe "VCBATT1 ECU: start PCSOV shutdown self test";
CM_ SG_ 1119 VCBATT1_startPCSDomainOvervoltag "VCBATT1 ECU: start PCS domain overvoltage self test";
CM_ SG_ 1119 VCBATT1_startBattDomainUnde_0001 "VCBATT1 ECU: start batt domain undervoltage VC left self test";
CM_ SG_ 1119 VCBATT1_startPCSDomainUndervolta "VCBATT1 ECU: start PCS domain undervoltage self test";
CM_ SG_ 1119 VCBATT1_startVCFrontBridgeEFuseA "VCBATT1 ECU: start VC front bridge e fuse ASIC self test";
CM_ SG_ 1119 VCBATT1_battDomainOvercurrentSel "Self-Test Result.";
CM_ SG_ 1119 VCBATT1_battDomainOvercurre_0001 "Self-Test State; raw 4 = signal not available (SNA)";
CM_ SG_ 1119 VCBATT1_battDomainOvervoltageSel "Self-Test Result.";
CM_ SG_ 1119 VCBATT1_battDomainOvervolta_0001 "Self-Test State; raw 4 = signal not available (SNA)";
CM_ SG_ 1119 VCBATT1_battDomainUndervoltageSe "Self-Test Result.";
CM_ SG_ 1119 VCBATT1_battDomainUndervolt_0001 "Self-Test State; raw 4 = signal not available (SNA)";
CM_ SG_ 1119 VCBATT1_dualPowerLoadsSelfTestRe "Self-Test Result.";
CM_ SG_ 1119 VCBATT1_dualPowerLoadsSelfTestSt "Self-Test State; raw 4 = signal not available (SNA)";
CM_ SG_ 1119 VCBATT1_vcbattBridgeEFuseASICSel "Self-Test Result.";
CM_ SG_ 1119 VCBATT1_vcbattBridgeEFuseAS_0001 "Self-Test State; raw 4 = signal not available (SNA)";
CM_ SG_ 1119 VCBATT1_uvProtectionState "VCBATT1 ECU: uv protection state";
CM_ SG_ 1119 VCBATT1_undervoltageSelfTestFaul "VCBATT1 ECU: undervoltage self test fault injection ready";
CM_ SG_ 1119 VC_selfTestsRunningMode "VCBATT1 ECU: self tests running mode";
CM_ BO_ 801 "Front body controller message: sensors; frame length observed on a vehicle bus";
CM_ SG_ 801 VCFRONT_tempCoolantBatInlet "Battery measured inlet coolant temperature; raw 1023 = signal not available (SNA)";
CM_ SG_ 801 VCFRONT_tempCoolantPTInlet "Powertrain measured inlet coolant temperature; raw 2047 = signal not available (SNA)";
CM_ SG_ 801 VCFRONT_coolantLevel "Front body controller: coolant level";
CM_ SG_ 801 VCFRONT_brakeFluidLevel "Reports detected brake fluid level at the fluid reservoir; raw 0 = signal not available (SNA)";
CM_ SG_ 801 VCFRONT_tempAmbient "Front body controller: temp ambient; raw 0 = signal not available (SNA)";
CM_ SG_ 801 VCFRONT_washerFluidLevel "Indicates that the sensor has detected low windshield washer fluid; raw 0 = signal not available (SNA)";
CM_ SG_ 801 VCFRONT_tempAmbientFiltered "Filtered ambient temperature based on vehicle speed; raw 0 = signal not available (SNA)";
CM_ SG_ 801 VCFRONT_battSensorIrrational "Front body controller: batt sensor irrational";
CM_ SG_ 801 VCFRONT_ptSensorIrrational "Front body controller: pt sensor irrational";
CM_ SG_ 801 VCFRONT_sensorsCounter "Front body controller: sensors counter";
CM_ SG_ 801 VCFRONT_sensorsChecksum "Front body controller: sensors checksum";
CM_ BO_ 1349 "Front body controller message: system status; frame length observed on a vehicle bus";
CM_ SG_ 1349 VCFRONT_systemStatusMuxIndex "Front body controller: system status mux index";
CM_ SG_ 1349 VCFRONT_systemStatusCounter "Front body controller: system status counter";
CM_ SG_ 1349 VCFRONT_systemStatusChecksum "Front body controller: system status checksum";
CM_ SG_ 1349 VCFRONT_loadShedReason "Front body controller: load shed reason";
CM_ SG_ 1349 VCFRONT_VCRightEFuseLoadShedStag "Front body controller: VC right e fuse load shed stage";
CM_ SG_ 1349 VCFRONT_VCLeftEFuseLoadShedStage "Front body controller: VC left e fuse load shed stage";
CM_ SG_ 1349 VCFRONT_DCDCSaturationLoadShedSt "Front body controller: DCDC saturation load shed stage";
CM_ SG_ 1349 VCFRONT_vehicleLoadShedStage "Front body controller: vehicle load shed stage";
CM_ SG_ 1349 VCFRONT_HVFaultVehicleLoadShedRe "Front body controller: HV fault vehicle load shed request";
CM_ SG_ 1349 VCFRONT_postCrashVehicleLoadShed "Front body controller: post crash vehicle load shed active";
CM_ SG_ 1349 VCFRONT_HVFaultVehicleLoadShedAc "Front body controller: HV fault vehicle load shed active";
CM_ SG_ 1349 VCFRONT_factoryVehicleLoadShedAc "Indicates that vehicle is factory load shedding";
CM_ SG_ 1349 VCFRONT_anyVehicleLoadShedActive "Front body controller: any vehicle load shed active";
CM_ SG_ 1349 VCFRONT_DIVehLoadShedActive "Front body controller: DI veh load shed active";
CM_ SG_ 1349 VCFRONT_HVFaultLoadShedStateDBG "Front body controller: HV fault load shed state DBG";
CM_ SG_ 1349 VCFRONT_LVUnhealthyVehicleLoadSh "Front body controller: LV unhealthy vehicle load shed active";
CM_ SG_ 1349 VCFRONT_loadShedStsCondenserFan "Front body controller: load shed sts condenser fan";
CM_ SG_ 1349 VCFRONT_loadShedStsPTPump "Front body controller: load shed sts PT pump";
CM_ SG_ 1349 VCFRONT_loadShedMCUAudio "Front body controller: load shed MCU audio";
CM_ SG_ 1349 VCFRONT_loadShedHVDownTriggerDBG "Front body controller: load shed HV down trigger DBG";
CM_ SG_ 1349 VCFRONT_loadShedPCSSatTriggerDBG "Front body controller: load shed PCS sat trigger DBG";
CM_ SG_ 1349 VCFRONT_loadShedStsBatteryPump "Front body controller: load shed sts battery pump";
CM_ SG_ 1349 VCFRONT_loadShedStsAPGlassHeater "Front body controller: load shed sts AP glass heater";
CM_ SG_ 1349 VCFRONT_loadShedStsMCUGraphics "Front body controller: load shed sts MCU graphics";
CM_ SG_ 1349 VCFRONT_IBSCurrentRMS_loadShed "Front body controller: IBS current RMS load shed";
CM_ SG_ 1349 VCFRONT_loadShedAhLeakyBktCntDBG "Front body controller: load shed ah leaky bkt cnt DBG";
CM_ SG_ 1349 VCFRONT_loadShedPcs "Front body controller: load shed pcs";
CM_ SG_ 1349 VCFRONT_loadShedGTWDownstrmRails "Front body controller: load shed GTW downstrm rails";
CM_ SG_ 1349 VCFRONT_loadShedPCSMIATriggerDBG "Front body controller: load shed PCSMIA trigger DBG";
CM_ SG_ 1349 VCFRONT_loadShedTAS "Front body controller: load shed TAS";
CM_ SG_ 1349 VCFRONT_loadShedBackStopBktCntDB "Front body controller: load shed back stop bkt cnt DBG";
CM_ SG_ 1349 VCFRONT_loadShedPCSLeakyBktCtDBG "Front body controller: load shed PCS leaky bkt ct DBG";
CM_ SG_ 1349 VCFRONT_loadShedUI "Front body controller: load shed UI";
CM_ SG_ 1349 VCFRONT_loadShedAutoPilot "Front body controller: load shed auto pilot";
CM_ BO_ 929 "Front body controller message: vehicle status; frame length observed on a vehicle bus";
CM_ SG_ 929 VCFRONT_vehicleStatusMuxIndex "Front body controller: vehicle status mux index";
CM_ SG_ 929 VCFRONT_vehicleStatusCounter "Front body controller: vehicle status counter";
CM_ SG_ 929 VCFRONT_vehicleStatusChecksum "Front body controller: vehicle status checksum";
CM_ SG_ 929 VCFRONT_preconditionRequest "Front body controller: precondition request";
CM_ SG_ 929 VCFRONT_APGlassHeaterState "Front body controller: AP glass heater state; raw 0 = signal not available (SNA)";
CM_ SG_ 929 VCFRONT_thermalSystemType "Front body controller: thermal system type; raw 1 = signal not available (SNA)";
CM_ SG_ 929 VCFRONT_standbySupplySupported "Front body controller: standby supply supported";
CM_ SG_ 929 VCFRONT_driverPresent "Front body controller: driver present";
CM_ SG_ 929 VCFRONT_passengerPresent "Front body controller: passenger present";
CM_ SG_ 929 VCFRONT_accPlusAvailable "Front body controller: acc plus available";
CM_ SG_ 929 VCFRONT_diPowerOnState "Front body controller: di power on state";
CM_ SG_ 929 VCFRONT_12vStatusForDrive "Front body controller: 12v status for drive";
CM_ SG_ 929 VCFRONT_dcr12VMilliOhms "Front body controller: dcr12 v milli ohms";
CM_ SG_ 929 VC_userPresenceState "User presence state";
CM_ SG_ 929 VCFRONT_factoryLimitsOverrideOk "Front body controller: factory limits override ok";
CM_ SG_ 929 VCFRONT_ota12VSupportRequest "Front body controller: ota12 v support request";
CM_ SG_ 929 VCFRONT_driverBuckleStatus "Front body controller: driver buckle status";
CM_ SG_ 929 VCFRONT_driverDoorStatus "Front body controller: driver door status";
CM_ SG_ 929 VCFRONT_driverUnbuckled "Front body controller: driver unbuckled; raw 2 = signal not available (SNA)";
CM_ SG_ 929 VCFRONT_passengerUnbuckled "Front body controller: passenger unbuckled; raw 2 = signal not available (SNA)";
CM_ SG_ 929 VCFRONT_2RowLeftUnbuckled "Front body controller: 2 row left unbuckled; raw 2 = signal not available (SNA)";
CM_ SG_ 929 VCFRONT_2RowCenterUnbuckled "Front body controller: 2 row center unbuckled; raw 2 = signal not available (SNA)";
CM_ SG_ 929 VCFRONT_2RowRightUnbuckled "Front body controller: 2 row right unbuckled; raw 2 = signal not available (SNA)";
CM_ SG_ 929 VCFRONT_pcsEFuseVoltage "Front body controller: pcs e fuse voltage; raw 1023 = signal not available (SNA)";
CM_ SG_ 929 VCFRONT_bmsHvChargeEnable "Front body controller: bms hv charge enable";
CM_ SG_ 929 VCFRONT_3RowLeftUnbuckled "Indication that the third row left passenger has unbuckled their seat belt; raw 2 = signal not available (SNA)";
CM_ SG_ 929 VCFRONT_3RowRightUnbuckled "Indication that the third row right passenger has unbuckled their seat belt; raw 2 = signal not available (SNA)";
CM_ SG_ 929 VCFRONT_maxBattHeatRejection "Radiator max heat rejection estimated at zero vehicle speed.";
CM_ SG_ 929 VCFRONT_hvacReqBattCoolOutTemp "Battery outlet coolant temp target to allow HVAC min comfort";
CM_ SG_ 929 VCFRONT_PCSCurrent "Front body controller: PCS current";
CM_ SG_ 929 VCFRONT_refSystemNominal "Front body controller: ref system nominal";
CM_ SG_ 929 VCFRONT_driverEnteredCabinEstima "Front body controller: driver entered cabin estimate DBG";
CM_ SG_ 929 VCFRONT_anySWEFuseActive "Front body controller: any SWE fuse active";
CM_ SG_ 929 VCFRONT_hpBattHeatingPowerTrgt "Reports the heat pump battery heating power target.";
CM_ BO_ 258 "Left body controller message: door status; frame length observed on a vehicle bus";
CM_ SG_ 258 VCLEFT_doorClosureStatusFront "Status of the door from a closures perspective; raw 0 = signal not available (SNA)";
CM_ SG_ 258 VCLEFT_doorClosureStatusRear "Status of the door from a closures perspective; raw 0 = signal not available (SNA)";
CM_ SG_ 258 VCLEFT_frontLatchSwitch "State of front left door latch switch representing door open/closed. 0 is open and 1 is closed";
CM_ SG_ 258 VCLEFT_rearLatchSwitch "State of rear left door latch switch representing door open/closed. 0 is open and 1 is closed";
CM_ SG_ 258 VCLEFT_frontHandlePulled "Left body controller: front handle pulled";
CM_ SG_ 258 VCLEFT_rearHandlePulled "Left body controller: rear handle pulled";
CM_ SG_ 258 VCLEFT_frontRelActuatorSwitch "State of front left door latch switch representing latch arm/unarmed. Disarms while door handle is pulled.";
CM_ SG_ 258 VCLEFT_rearRelActuatorSwitch "State of rear left door latch switch representing latch arm/unarmed. Disarms while door handle is pulled";
CM_ SG_ 258 VCLEFT_frontLatchStatus "Status of left front door latch; raw 0 = signal not available (SNA)";
CM_ SG_ 258 VCLEFT_rearLatchStatus "Status of rear left door latch; raw 0 = signal not available (SNA)";
CM_ SG_ 258 VCLEFT_lastDoorReqSourceFront "last source of front door open request";
CM_ SG_ 258 VCLEFT_lastDoorReqSourceRear "last source of rear door open request";
CM_ SG_ 258 VCLEFT_frontIntSwitchFaulted "Indicates if the front door interior button is faulted";
CM_ SG_ 258 VCLEFT_rearIntSwitchFaulted "Indicates if the rear door interior button is faulted";
CM_ SG_ 258 VCLEFT_frontIntSwitchPressed "Left body controller: front int switch pressed";
CM_ SG_ 258 VCLEFT_rearIntSwitchPressed "Left body controller: rear int switch pressed";
CM_ SG_ 258 VCLEFT_mirrorTiltXPosition "Value representing left side view mirror tilt horizontal position";
CM_ SG_ 258 VCLEFT_mirrorTiltYPosition "Value representing left side view mirror tilt vertical position";
CM_ SG_ 258 VCLEFT_mirrorState "State of the left side view mirror.";
CM_ SG_ 258 VCLEFT_mirrorFoldState "Fold state for the left side view mirror";
CM_ SG_ 258 VCLEFT_mirrorRecallState "State of Mirror Recall.";
CM_ SG_ 258 VCLEFT_mirrorHeatState "Left body controller: mirror heat state; raw 0 = signal not available (SNA)";
CM_ SG_ 258 VCLEFT_rearHandlePulledPersist "Left body controller: rear handle pulled persist";
CM_ SG_ 258 VCLEFT_frontHandlePulledPersist "Left body controller: front handle pulled persist";
CM_ SG_ 258 VCLEFT_mirrorDipped "Reports if the side view mirrors in are in the dipped position.";
CM_ BO_ 995 "Right body controller message: light status; frame length observed on a vehicle bus";
CM_ SG_ 995 VCRIGHT_brakeLightStatus "Status of rear right brake light source; raw 3 = signal not available (SNA)";
CM_ SG_ 995 VCRIGHT_tailLightStatus "Status of right tail (rear position) light source; raw 3 = signal not available (SNA)";
CM_ SG_ 995 VCRIGHT_turnSignalStatus "Status of rear right turn signal light source; raw 3 = signal not available (SNA)";
CM_ SG_ 995 VCRIGHT_reverseLightStatus "Status of the reverse light source(s); raw 3 = signal not available (SNA)";
CM_ SG_ 995 VCRIGHT_rearFogLightStatus "The desired on/off state of the rear fog light source(s); raw 3 = signal not available (SNA)";
CM_ SG_ 995 VCRIGHT_leftInteriorTrunkLightRe "Right body controller: left interior trunk light req";
CM_ SG_ 995 VCRIGHT_audioCurrentSpikeDetecte "Right body controller: audio current spike detected";
CM_ BO_ 1066 "Vehicle security controller message: TPMS connection data; frame length from the layout, not yet observed on a vehicle bus";
CM_ SG_ 1066 VCSEC_TPMSSensorState0 "Indicates the sensors pairing/connectivity status";
CM_ SG_ 1066 VCSEC_TPMSRSSI0 "Received Signal Strength Index reported by sensor.";
CM_ SG_ 1066 VCSEC_TPMSConnectionTypeCurrent0 "Vehicle security controller: TPMS connection type current0";
CM_ SG_ 1066 VCSEC_TPMSConnectionTypeDesired0 "Vehicle security controller: TPMS connection type desired0";
CM_ SG_ 1066 VCSEC_TPMSSensorState1 "Indicates the sensors pairing/connectivity status";
CM_ SG_ 1066 VCSEC_TPMSRSSI1 "Received Signal Strength Index reported by sensor.";
CM_ SG_ 1066 VCSEC_TPMSConnectionTypeCurrent1 "Vehicle security controller: TPMS connection type current1";
CM_ SG_ 1066 VCSEC_TPMSConnectionTypeDesired1 "Vehicle security controller: TPMS connection type desired1";
CM_ SG_ 1066 VCSEC_TPMSSensorState2 "Indicates the sensors pairing/connectivity status";
CM_ SG_ 1066 VCSEC_TPMSRSSI2 "Received Signal Strength Index reported by sensor.";
CM_ SG_ 1066 VCSEC_TPMSConnectionTypeCurrent2 "Vehicle security controller: TPMS connection type current2";
CM_ SG_ 1066 VCSEC_TPMSConnectionTypeDesired2 "Vehicle security controller: TPMS connection type desired2";
CM_ SG_ 1066 VCSEC_TPMSSensorState3 "Indicates the sensors pairing/connectivity status";
CM_ SG_ 1066 VCSEC_TPMSRSSI3 "Received Signal Strength Index reported by sensor.";
CM_ SG_ 1066 VCSEC_TPMSConnectionTypeCurrent3 "Vehicle security controller: TPMS connection type current3";
CM_ SG_ 1066 VCSEC_TPMSConnectionTypeDesired3 "Vehicle security controller: TPMS connection type desired3";
CM_ SG_ 1066 VCSEC_TPMSSensorPresence0 "Indicates the sensors detection status";
CM_ SG_ 1066 VCSEC_TPMSSensorPresence1 "Indicates the sensors detection status";
CM_ SG_ 1066 VCSEC_TPMSSensorPresence2 "Indicates the sensors detection status";
CM_ SG_ 1066 VCSEC_TPMSSensorPresence3 "Indicates the sensors detection status";
CM_ BO_ 1817 "Vehicle security controller message: debug100ms; frame length from the layout, not yet observed on a vehicle bus";
CM_ SG_ 1817 VCSEC_debug100msIndex "Vehicle security controller: debug100ms index";
CM_ SG_ 1817 VCSEC_walkAwayLockKeyState "Walk away lock key state of the vehicle";
CM_ SG_ 1817 VCSEC_thresholdOffsetVersion "Vehicle security controller: threshold offset version";
CM_ SG_ 1817 VCSEC_walkAwayLockState "Walk away lock state of the vehicle";
CM_ SG_ 1817 VCSEC_rssi0WLEntry "Whitelist entry of the rssi0 device";
CM_ SG_ 1817 VCSEC_endpointLayout "Vehicle security controller: endpoint layout";
CM_ SG_ 1817 VCSEC_rssi1WLEntry "Whitelist entry of the rssi1 device";
CM_ SG_ 1817 VCSEC_rssi2WLEntry "Whitelist entry of the rssi2 device";
CM_ SG_ 1817 VCSEC_walkUpUnlockState "Status of walk up unlock state";
CM_ SG_ 1817 VCSEC_algoHighThreshLeft "Vehicle security controller: algo high thresh left";
CM_ SG_ 1817 VCSEC_algoHighThreshRight "Vehicle security controller: algo high thresh right";
CM_ SG_ 1817 VCSEC_algoHighThreshCenter "Vehicle security controller: algo high thresh center";
CM_ SG_ 1817 VCSEC_pollingReason "Reason that the vehicle is currently polling for location";
CM_ SG_ 1817 VCSEC_numberOfPubKeysOnWhitelist "Number of public keys on keys whitelist.";
CM_ SG_ 1817 VCSEC_thermalDetectState "Reports the current state of thermal detection.";
CM_ SG_ 1817 VCSEC_chargeHandleMitigationActi "Vehicle security controller: charge handle mitigation active";
CM_ SG_ 1817 VCSEC_device0Offset "Vehicle security controller: device0 offset";
CM_ SG_ 1817 VCSEC_device1Offset "Vehicle security controller: device1 offset";
CM_ SG_ 1817 VCSEC_device2Offset "Vehicle security controller: device2 offset";
BA_DEF_ "BusType" STRING;
BA_DEF_ "DBName" STRING;
BA_DEF_ "Baudrate" INT 0 1000000;
BA_DEF_ "BaudrateCANFD" INT 0 16000000;
BA_DEF_ "Manufacturer" STRING;
BA_DEF_ "FirmwareVersion" STRING;
BA_DEF_ "VehicleModel" STRING;
BA_DEF_ BU_ "ECU" STRING;
BA_DEF_ BO_ "GenMsgCycleTime" INT 0 3600000;
BA_DEF_ BO_ "GenMsgSendType" ENUM "Cyclic","NotUsed","NotUsed","NotUsed","NotUsed","NotUsed","NotUsed","IfActive","NoMsgSendType","NotUsed";
BA_DEF_ BO_ "VFrameFormat" ENUM "StandardCAN","ExtendedCAN","reserved","J1939PG","reserved","reserved","reserved","reserved","reserved","reserved","reserved","reserved","reserved","reserved","StandardCAN_FD","ExtendedCAN_FD";
BA_DEF_ BO_ "CANFD_BRS" ENUM "0","1";
BA_DEF_ SG_ "GenSigSNA" STRING;
BA_DEF_ SG_ "SystemSignalLongSymbol" STRING;
BA_DEF_ SG_ "Confidence" ENUM "validated","plausible","layout-only","contradicted";
BA_DEF_DEF_ "BusType" "CAN";
BA_DEF_DEF_ "DBName" "";
BA_DEF_DEF_ "Baudrate" 500000;
BA_DEF_DEF_ "BaudrateCANFD" 2000000;
BA_DEF_DEF_ "Manufacturer" "";
BA_DEF_DEF_ "FirmwareVersion" "";
BA_DEF_DEF_ "VehicleModel" "";
BA_DEF_DEF_ "ECU" "";
BA_DEF_DEF_ "GenMsgCycleTime" 0;
BA_DEF_DEF_ "GenMsgSendType" "NoMsgSendType";
BA_DEF_DEF_ "VFrameFormat" "StandardCAN";
BA_DEF_DEF_ "CANFD_BRS" "1";
BA_DEF_DEF_ "GenSigSNA" "";
BA_DEF_DEF_ "SystemSignalLongSymbol" "";
BA_DEF_DEF_ "Confidence" "layout-only";
BA_ "DBName" "Bayberry_VEH";
BA_ "Manufacturer" "Tesla";
BA_ "FirmwareVersion" "2026.26.6.5";
BA_ "VehicleModel" "Bayberry";
BA_ "ECU" BU_ BMS "BMS";
BA_ "ECU" BU_ CC "CC";
BA_ "ECU" BU_ CP "CP";
BA_ "ECU" BU_ EPBR "EPBR";
BA_ "ECU" BU_ GTW "GTW";
BA_ "ECU" BU_ HVP "HVP";
BA_ "ECU" BU_ ICR "ICR";
BA_ "ECU" BU_ PCS "PCS";
BA_ "ECU" BU_ VCBATT1 "VCBATT1";
BA_ "ECU" BU_ VCFRONT "VCFRONT";
BA_ "ECU" BU_ VCLEFT "VCLEFT";
BA_ "ECU" BU_ VCRIGHT "VCRIGHT";
BA_ "ECU" BU_ VCSEC "VCSEC";
BA_ "GenMsgCycleTime" BO_ 594 100;
BA_ "GenMsgSendType" BO_ 594 0;
BA_ "GenMsgCycleTime" BO_ 754 100;
BA_ "GenMsgSendType" BO_ 754 0;
BA_ "GenMsgCycleTime" BO_ 812 1000;
BA_ "GenMsgSendType" BO_ 812 0;
BA_ "GenMsgCycleTime" BO_ 669 100;
BA_ "GenMsgSendType" BO_ 669 0;
BA_ "GenMsgCycleTime" BO_ 1885 200;
BA_ "GenMsgSendType" BO_ 1885 0;
BA_ "GenMsgCycleTime" BO_ 989 1000;
BA_ "GenMsgSendType" BO_ 989 0;
BA_ "GenMsgCycleTime" BO_ 893 1000;
BA_ "GenMsgSendType" BO_ 893 0;
BA_ "GenMsgCycleTime" BO_ 2024 1000;
BA_ "GenMsgSendType" BO_ 2024 0;
BA_ "GenMsgCycleTime" BO_ 1914 1000;
BA_ "GenMsgSendType" BO_ 1914 0;
BA_ "GenMsgCycleTime" BO_ 664 100;
BA_ "GenMsgSendType" BO_ 664 0;
BA_ "GenMsgCycleTime" BO_ 676 1000;
BA_ "GenMsgSendType" BO_ 676 0;
BA_ "GenMsgCycleTime" BO_ 819 500;
BA_ "GenMsgSendType" BO_ 819 0;
BA_ "GenMsgCycleTime" BO_ 826 1000;
BA_ "GenMsgSendType" BO_ 826 0;
BA_ "GenMsgCycleTime" BO_ 1119 500;
BA_ "GenMsgSendType" BO_ 1119 0;
BA_ "GenMsgCycleTime" BO_ 801 1000;
BA_ "GenMsgSendType" BO_ 801 0;
BA_ "GenMsgCycleTime" BO_ 1349 33;
BA_ "GenMsgSendType" BO_ 1349 0;
BA_ "GenMsgCycleTime" BO_ 929 50;
BA_ "GenMsgSendType" BO_ 929 0;
BA_ "GenMsgCycleTime" BO_ 258 100;
BA_ "GenMsgSendType" BO_ 258 0;
BA_ "GenMsgCycleTime" BO_ 995 200;
BA_ "GenMsgSendType" BO_ 995 0;
BA_ "GenMsgCycleTime" BO_ 1066 200;
BA_ "GenMsgSendType" BO_ 1066 0;
BA_ "GenMsgCycleTime" BO_ 1817 50;
BA_ "GenMsgSendType" BO_ 1817 0;
BA_ "Confidence" SG_ 594 BMS_maxRegenPower 0;
BA_ "Confidence" SG_ 594 BMS_maxDischargePower 0;
BA_ "Confidence" SG_ 594 BMS_maxStationaryHeatPower 0;
BA_ "Confidence" SG_ 594 BMS_powerLimitsState 0;
BA_ "Confidence" SG_ 594 BMS_totalHvPowerBudget 0;
BA_ "Confidence" SG_ 594 BMS_notEnoughPowerForHeatPump 0;
BA_ "Confidence" SG_ 754 BMS_nmGoingToSleep 0;
BA_ "Confidence" SG_ 754 BMS_nmWakeUpBus 0;
BA_ "Confidence" SG_ 754 BMS_hvsBusAsleep 0;
BA_ "Confidence" SG_ 754 BMS_nmKeepAwakeReason 0;
BA_ "GenSigSNA" SG_ 754 BMS_nmKeepAwakeReason "0";
BA_ "Confidence" SG_ 754 BMS_nmWakeUpReason 0;
BA_ "Confidence" SG_ 812 CC_logIndex 1;
BA_ "Confidence" SG_ 812 CC_activeConnectorID 0;
BA_ "Confidence" SG_ 812 CC_temperature1 0;
BA_ "Confidence" SG_ 812 CC_temperature2 0;
BA_ "Confidence" SG_ 812 CC_temperature3 0;
BA_ "Confidence" SG_ 812 CC_contactor1Closed 0;
BA_ "Confidence" SG_ 812 CC_contactor2Closed 0;
BA_ "Confidence" SG_ 812 CC_temperature4 0;
BA_ "Confidence" SG_ 812 CC_conn1Current 0;
BA_ "GenSigSNA" SG_ 812 CC_conn1Current "255";
BA_ "Confidence" SG_ 812 CC_conn2Current 0;
BA_ "GenSigSNA" SG_ 812 CC_conn2Current "255";
BA_ "Confidence" SG_ 812 CC_conn3Current 0;
BA_ "GenSigSNA" SG_ 812 CC_conn3Current "255";
BA_ "Confidence" SG_ 812 CC_conn4Current 0;
BA_ "GenSigSNA" SG_ 812 CC_conn4Current "255";
BA_ "Confidence" SG_ 812 CC_lifetimei2t 0;
BA_ "Confidence" SG_ 812 CC_lifetimeCtrCycles 0;
BA_ "Confidence" SG_ 812 CC_lifetimeCtrCyclesLoaded 0;
BA_ "Confidence" SG_ 812 CC_lifetimeAlertCount 0;
BA_ "Confidence" SG_ 812 CC_lifetimeThermalFoldbacks 0;
BA_ "Confidence" SG_ 812 CC_lifetimeAvgStartupTemp 0;
BA_ "Confidence" SG_ 669 CP_evseOutputDcCurrent 0;
BA_ "Confidence" SG_ 669 CP_evseOutputDcVoltage 0;
BA_ "Confidence" SG_ 669 CP_evseOutputDcCurrentStale 0;
BA_ "Confidence" SG_ 669 CP_evRelocationRecommended 0;
BA_ "Confidence" SG_ 669 CP_evseDeratingReason 0;
BA_ "Confidence" SG_ 1885 CP_loggingFastSelect 1;
BA_ "Confidence" SG_ 1885 CP_inductiveSensor_raw 0;
BA_ "Confidence" SG_ 1885 CP_doorOpenActuationTime 0;
BA_ "Confidence" SG_ 1885 CP_doorCloseActuationTime 0;
BA_ "Confidence" SG_ 1885 CP_chargeCableSecured 0;
BA_ "Confidence" SG_ 1885 CP_chargeCablePresent 0;
BA_ "Confidence" SG_ 1885 CP_latchCheckAvailable 0;
BA_ "Confidence" SG_ 1885 CP_UHF_controlState 0;
BA_ "Confidence" SG_ 1885 CP_proximityV 0;
BA_ "Confidence" SG_ 1885 CP_proximityV_GBCC1 0;
BA_ "Confidence" SG_ 1885 CP_proximityV_GBCC2 0;
BA_ "Confidence" SG_ 1885 CP_doorPot 0;
BA_ "Confidence" SG_ 1885 CP_doorPresenceSensorV 0;
BA_ "Confidence" SG_ 1885 CP_doorOpenRequest 0;
BA_ "Confidence" SG_ 1885 CP_doorOpenEndOfDriveReason 0;
BA_ "Confidence" SG_ 1885 CP_coverClosed 0;
BA_ "Confidence" SG_ 1885 CP_doorCloseEndOfDriveReason 0;
BA_ "Confidence" SG_ 1885 CP_doorCloseRequest 0;
BA_ "Confidence" SG_ 1885 CP_latchDisengagingTime 0;
BA_ "Confidence" SG_ 1885 CP_latchEngagingTime 0;
BA_ "Confidence" SG_ 1885 CP_latchDisengagingStopReason 0;
BA_ "Confidence" SG_ 1885 CP_latchEngagingStopReason 0;
BA_ "Confidence" SG_ 1885 CP_pilotUnlatchRequestActive 0;
BA_ "Confidence" SG_ 1885 CP_doorIdDetectionState 0;
BA_ "GenSigSNA" SG_ 1885 CP_doorIdDetectionState "0";
BA_ "Confidence" SG_ 1885 CP_doorIdDetectedBin 0;
BA_ "Confidence" SG_ 1885 CP_semiV2LatchNonLinear 0;
BA_ "Confidence" SG_ 989 CP_loggingSlowSelect 1;
BA_ "Confidence" SG_ 989 CP_UHF_chipState 0;
BA_ "Confidence" SG_ 989 CP_UHF_rssi 0;
BA_ "Confidence" SG_ 989 CP_UHF_rxOverflow 0;
BA_ "Confidence" SG_ 989 CP_UHF_rxNumBytes 0;
BA_ "Confidence" SG_ 989 CP_UHF_selfTestRssi 0;
BA_ "Confidence" SG_ 989 CP_latchI 0;
BA_ "Confidence" SG_ 989 CP_inlet1HarnessIdState 0;
BA_ "GenSigSNA" SG_ 989 CP_inlet1HarnessIdState "0";
BA_ "Confidence" SG_ 989 CP_inlet1HarnessIdValue 0;
BA_ "Confidence" SG_ 989 CP_inlet2HarnessIdState 0;
BA_ "GenSigSNA" SG_ 989 CP_inlet2HarnessIdState "0";
BA_ "Confidence" SG_ 989 CP_inlet2HarnessIdValue 0;
BA_ "Confidence" SG_ 989 CP_inletHeaterState 0;
BA_ "Confidence" SG_ 989 CP_inletHeaterDuty 0;
BA_ "Confidence" SG_ 989 CP_5vSwV 0;
BA_ "Confidence" SG_ 989 CP_boardTemperature 0;
BA_ "Confidence" SG_ 989 CP_refVoltage 0;
BA_ "Confidence" SG_ 989 CP_doorId_intervalMin10s 0;
BA_ "Confidence" SG_ 989 CP_doorId_intervalMax10s 0;
BA_ "Confidence" SG_ 989 CP_wakeOnPushCounter 0;
BA_ "Confidence" SG_ 989 CP_doorPushLockoutActive 0;
BA_ "Confidence" SG_ 989 CP_nvm_dataValid 0;
BA_ "Confidence" SG_ 989 CP_nvm_doorOpenCycles 0;
BA_ "Confidence" SG_ 989 CP_nvm_doorCloseCycles 0;
BA_ "Confidence" SG_ 989 CP_nvm_doorOpen 0;
BA_ "Confidence" SG_ 989 CP_nvm_doorPresent 0;
BA_ "Confidence" SG_ 989 CP_nvm_doorPresentValid 0;
BA_ "Confidence" SG_ 989 CP_nvm_badPilotDiodeDetected 0;
BA_ "Confidence" SG_ 989 CP_nvm_pilotDiodeFaultCount 0;
BA_ "Confidence" SG_ 989 CP_doorOpenLimiterMaxCount 0;
BA_ "Confidence" SG_ 989 CP_doorOpenLimiterMaxRequestType 0;
BA_ "Confidence" SG_ 989 CP_doorCloseLimiterMaxCount 0;
BA_ "Confidence" SG_ 989 CP_doorCloseLimiterMaxRequestTyp 0;
BA_ "SystemSignalLongSymbol" SG_ 989 CP_doorCloseLimiterMaxRequestTyp "CP_doorCloseLimiterMaxRequestType";
BA_ "Confidence" SG_ 989 CP_proximityWakeCounter 0;
BA_ "Confidence" SG_ 893 CP_thermalStatusSelect 1;
BA_ "Confidence" SG_ 893 CP_pinTemperature1 0;
BA_ "Confidence" SG_ 893 CP_pinTemperature2 0;
BA_ "Confidence" SG_ 893 CP_pinTemperature3 0;
BA_ "Confidence" SG_ 893 CP_pinTemperature4 0;
BA_ "Confidence" SG_ 893 CP_pinTemp4Velocity 0;
BA_ "GenSigSNA" SG_ 893 CP_pinTemp4Velocity "511";
BA_ "Confidence" SG_ 2024 EPBR_infoIndex 1;
BA_ "Confidence" SG_ 2024 EPBR_infoBuildType 0;
BA_ "Confidence" SG_ 2024 EPBR_infoBuildConfigId 0;
BA_ "Confidence" SG_ 2024 EPBR_infoHardwareId 0;
BA_ "Confidence" SG_ 2024 EPBR_infoComponentId 0;
BA_ "Confidence" SG_ 2024 EPBR_infoPcbaId 0;
BA_ "Confidence" SG_ 2024 EPBR_infoAssemblyId 0;
BA_ "GenSigSNA" SG_ 2024 EPBR_infoAssemblyId "255";
BA_ "Confidence" SG_ 2024 EPBR_infoUsageId 0;
BA_ "Confidence" SG_ 2024 EPBR_infoSubUsageId 0;
BA_ "Confidence" SG_ 2024 EPBR_infoAppCrc 0;
BA_ "Confidence" SG_ 2024 EPBR_infoAppGitHash 0;
BA_ "Confidence" SG_ 2024 EPBR_infoBootGitHash 0;
BA_ "Confidence" SG_ 2024 EPBR_infoPlatformType 0;
BA_ "Confidence" SG_ 2024 EPBR_infoBootUdsProtoVersion 0;
BA_ "Confidence" SG_ 2024 EPBR_infoBootCrc 0;
BA_ "Confidence" SG_ 1914 HVP_log1HzIndex 1;
BA_ "Confidence" SG_ 1914 HVP_bmbAsicType 0;
BA_ "Confidence" SG_ 1914 HVP_shuntCurrentAuxLog 0;
BA_ "Confidence" SG_ 1914 HVP_pyroSquibResistance 0;
BA_ "GenSigSNA" SG_ 1914 HVP_pyroSquibResistance "65535";
BA_ "Confidence" SG_ 1914 HVP_shuntAsicChipXCoordinate 0;
BA_ "Confidence" SG_ 1914 HVP_shuntAsicChipYCoordinate 0;
BA_ "Confidence" SG_ 1914 HVP_hvilCalType 0;
BA_ "Confidence" SG_ 1914 HVP_gpioPcsDcdcPwmEnable 0;
BA_ "Confidence" SG_ 1914 HVP_gpioPcsChargePwmEnable 0;
BA_ "Confidence" SG_ 1914 HVP_gpioPcsEnable 0;
BA_ "Confidence" SG_ 1914 HVP_shuntAsicChipWaferNumber 0;
BA_ "Confidence" SG_ 1914 HVP_energyReserveMin 0;
BA_ "Confidence" SG_ 1914 HVP_energyReserveMax 0;
BA_ "Confidence" SG_ 1914 HVP_energyReserveAvg 0;
BA_ "Confidence" SG_ 664 ICR_sensorMode 0;
BA_ "Confidence" SG_ 664 ICR_blocked 0;
BA_ "GenSigSNA" SG_ 664 ICR_blocked "0";
BA_ "Confidence" SG_ 664 ICR_booted 0;
BA_ "Confidence" SG_ 664 ICR_rdMapDumpCompleted 0;
BA_ "Confidence" SG_ 664 ICR_algoVersion 0;
BA_ "Confidence" SG_ 664 ICR_l2HeapUsage 0;
BA_ "Confidence" SG_ 664 ICR_intrusionStatus 0;
BA_ "Confidence" SG_ 664 ICR_blockageScaledMLOutput 0;
BA_ "Confidence" SG_ 676 PCS_chgPhATemp 0;
BA_ "GenSigSNA" SG_ 676 PCS_chgPhATemp "1025";
BA_ "Confidence" SG_ 676 PCS_chgPhBTemp 0;
BA_ "GenSigSNA" SG_ 676 PCS_chgPhBTemp "1025";
BA_ "Confidence" SG_ 676 PCS_chgPhCTemp 0;
BA_ "GenSigSNA" SG_ 676 PCS_chgPhCTemp "1025";
BA_ "Confidence" SG_ 676 PCS_dcdcTemp 0;
BA_ "GenSigSNA" SG_ 676 PCS_dcdcTemp "1025";
BA_ "Confidence" SG_ 676 PCS_ambientTemp 0;
BA_ "GenSigSNA" SG_ 676 PCS_ambientTemp "1025";
BA_ "Confidence" SG_ 676 PCS_dcdcBusbarTemp 0;
BA_ "GenSigSNA" SG_ 676 PCS_dcdcBusbarTemp "511";
BA_ "Confidence" SG_ 819 UI_openChargePortDoorRequest 0;
BA_ "Confidence" SG_ 819 UI_closeChargePortDoorRequest 0;
BA_ "Confidence" SG_ 819 UI_chargeEnableRequest 0;
BA_ "Confidence" SG_ 819 UI_acChargeCurrentLimit 0;
BA_ "GenSigSNA" SG_ 819 UI_acChargeCurrentLimit "127";
BA_ "Confidence" SG_ 819 UI_chargeTerminationPct 0;
BA_ "Confidence" SG_ 819 UI_scheduledDepartureEnabled 0;
BA_ "Confidence" SG_ 819 UI_chargePortLatchRequest 0;
BA_ "Confidence" SG_ 819 UI_cpInletHeaterRequest 0;
BA_ "Confidence" SG_ 826 UI_ratedRange 0;
BA_ "Confidence" SG_ 826 UI_soe 0;
BA_ "Confidence" SG_ 826 UI_uSoe 0;
BA_ "Confidence" SG_ 1119 VCBATT1_LVSelfTestsChecksum 0;
BA_ "Confidence" SG_ 1119 VCBATT1_LVSelfTestsCounter 0;
BA_ "Confidence" SG_ 1119 VCBATT1_LVSelfTestsIndex 1;
BA_ "Confidence" SG_ 1119 VCBATT1_lvProtectionSelfTestsEna 0;
BA_ "SystemSignalLongSymbol" SG_ 1119 VCBATT1_lvProtectionSelfTestsEna "VCBATT1_lvProtectionSelfTestsEnabled";
BA_ "Confidence" SG_ 1119 VCBATT1_startBattDomainOvercurre 0;
BA_ "SystemSignalLongSymbol" SG_ 1119 VCBATT1_startBattDomainOvercurre "VCBATT1_startBattDomainOvercurrentSelfTest";
BA_ "Confidence" SG_ 1119 VCBATT1_startBattDomainOvervolta 0;
BA_ "SystemSignalLongSymbol" SG_ 1119 VCBATT1_startBattDomainOvervolta "VCBATT1_startBattDomainOvervoltageSelfTest";
BA_ "Confidence" SG_ 1119 VCBATT1_startBattDomainUndervolt 0;
BA_ "SystemSignalLongSymbol" SG_ 1119 VCBATT1_startBattDomainUndervolt "VCBATT1_startBattDomainUndervoltageSelfTest";
BA_ "Confidence" SG_ 1119 VCBATT1_startDualPowerLoadsSelfT 0;
BA_ "SystemSignalLongSymbol" SG_ 1119 VCBATT1_startDualPowerLoadsSelfT "VCBATT1_startDualPowerLoadsSelfTest";
BA_ "Confidence" SG_ 1119 VCBATT1_startVCBattBridgeEFuseAS 0;
BA_ "SystemSignalLongSymbol" SG_ 1119 VCBATT1_startVCBattBridgeEFuseAS "VCBATT1_startVCBattBridgeEFuseASICSelfTest";
BA_ "Confidence" SG_ 1119 VCBATT1_startPCSOVShutdownSelfTe 0;
BA_ "SystemSignalLongSymbol" SG_ 1119 VCBATT1_startPCSOVShutdownSelfTe "VCBATT1_startPCSOVShutdownSelfTest";
BA_ "Confidence" SG_ 1119 VCBATT1_startPCSDomainOvervoltag 0;
BA_ "SystemSignalLongSymbol" SG_ 1119 VCBATT1_startPCSDomainOvervoltag "VCBATT1_startPCSDomainOvervoltageSelfTest";
BA_ "Confidence" SG_ 1119 VCBATT1_startBattDomainUnde_0001 0;
BA_ "SystemSignalLongSymbol" SG_ 1119 VCBATT1_startBattDomainUnde_0001 "VCBATT1_startBattDomainUndervoltageVCLeftSelfTest";
BA_ "Confidence" SG_ 1119 VCBATT1_startPCSDomainUndervolta 0;
BA_ "SystemSignalLongSymbol" SG_ 1119 VCBATT1_startPCSDomainUndervolta "VCBATT1_startPCSDomainUndervoltageSelfTest";
BA_ "Confidence" SG_ 1119 VCBATT1_startVCFrontBridgeEFuseA 0;
BA_ "SystemSignalLongSymbol" SG_ 1119 VCBATT1_startVCFrontBridgeEFuseA "VCBATT1_startVCFrontBridgeEFuseASICSelfTest";
BA_ "Confidence" SG_ 1119 VCBATT1_battDomainOvercurrentSel 0;
BA_ "SystemSignalLongSymbol" SG_ 1119 VCBATT1_battDomainOvercurrentSel "VCBATT1_battDomainOvercurrentSelfTestResult";
BA_ "Confidence" SG_ 1119 VCBATT1_battDomainOvercurre_0001 0;
BA_ "GenSigSNA" SG_ 1119 VCBATT1_battDomainOvercurre_0001 "4";
BA_ "SystemSignalLongSymbol" SG_ 1119 VCBATT1_battDomainOvercurre_0001 "VCBATT1_battDomainOvercurrentSelfTestState";
BA_ "Confidence" SG_ 1119 VCBATT1_battDomainOvervoltageSel 0;
BA_ "SystemSignalLongSymbol" SG_ 1119 VCBATT1_battDomainOvervoltageSel "VCBATT1_battDomainOvervoltageSelfTestResult";
BA_ "Confidence" SG_ 1119 VCBATT1_battDomainOvervolta_0001 0;
BA_ "GenSigSNA" SG_ 1119 VCBATT1_battDomainOvervolta_0001 "4";
BA_ "SystemSignalLongSymbol" SG_ 1119 VCBATT1_battDomainOvervolta_0001 "VCBATT1_battDomainOvervoltageSelfTestState";
BA_ "Confidence" SG_ 1119 VCBATT1_battDomainUndervoltageSe 0;
BA_ "SystemSignalLongSymbol" SG_ 1119 VCBATT1_battDomainUndervoltageSe "VCBATT1_battDomainUndervoltageSelfTestResult";
BA_ "Confidence" SG_ 1119 VCBATT1_battDomainUndervolt_0001 0;
BA_ "GenSigSNA" SG_ 1119 VCBATT1_battDomainUndervolt_0001 "4";
BA_ "SystemSignalLongSymbol" SG_ 1119 VCBATT1_battDomainUndervolt_0001 "VCBATT1_battDomainUndervoltageSelfTestState";
BA_ "Confidence" SG_ 1119 VCBATT1_dualPowerLoadsSelfTestRe 0;
BA_ "SystemSignalLongSymbol" SG_ 1119 VCBATT1_dualPowerLoadsSelfTestRe "VCBATT1_dualPowerLoadsSelfTestResult";
BA_ "Confidence" SG_ 1119 VCBATT1_dualPowerLoadsSelfTestSt 0;
BA_ "GenSigSNA" SG_ 1119 VCBATT1_dualPowerLoadsSelfTestSt "4";
BA_ "SystemSignalLongSymbol" SG_ 1119 VCBATT1_dualPowerLoadsSelfTestSt "VCBATT1_dualPowerLoadsSelfTestState";
BA_ "Confidence" SG_ 1119 VCBATT1_vcbattBridgeEFuseASICSel 0;
BA_ "SystemSignalLongSymbol" SG_ 1119 VCBATT1_vcbattBridgeEFuseASICSel "VCBATT1_vcbattBridgeEFuseASICSelfTestResult";
BA_ "Confidence" SG_ 1119 VCBATT1_vcbattBridgeEFuseAS_0001 0;
BA_ "GenSigSNA" SG_ 1119 VCBATT1_vcbattBridgeEFuseAS_0001 "4";
BA_ "SystemSignalLongSymbol" SG_ 1119 VCBATT1_vcbattBridgeEFuseAS_0001 "VCBATT1_vcbattBridgeEFuseASICSelfTestState";
BA_ "Confidence" SG_ 1119 VCBATT1_uvProtectionState 0;
BA_ "Confidence" SG_ 1119 VCBATT1_undervoltageSelfTestFaul 0;
BA_ "SystemSignalLongSymbol" SG_ 1119 VCBATT1_undervoltageSelfTestFaul "VCBATT1_undervoltageSelfTestFaultInjectionReady";
BA_ "Confidence" SG_ 1119 VC_selfTestsRunningMode 0;
BA_ "Confidence" SG_ 801 VCFRONT_tempCoolantBatInlet 0;
BA_ "GenSigSNA" SG_ 801 VCFRONT_tempCoolantBatInlet "1023";
BA_ "Confidence" SG_ 801 VCFRONT_tempCoolantPTInlet 0;
BA_ "GenSigSNA" SG_ 801 VCFRONT_tempCoolantPTInlet "2047";
BA_ "Confidence" SG_ 801 VCFRONT_coolantLevel 0;
BA_ "Confidence" SG_ 801 VCFRONT_brakeFluidLevel 0;
BA_ "GenSigSNA" SG_ 801 VCFRONT_brakeFluidLevel "0";
BA_ "Confidence" SG_ 801 VCFRONT_tempAmbient 0;
BA_ "GenSigSNA" SG_ 801 VCFRONT_tempAmbient "0";
BA_ "Confidence" SG_ 801 VCFRONT_washerFluidLevel 0;
BA_ "GenSigSNA" SG_ 801 VCFRONT_washerFluidLevel "0";
BA_ "Confidence" SG_ 801 VCFRONT_tempAmbientFiltered 0;
BA_ "GenSigSNA" SG_ 801 VCFRONT_tempAmbientFiltered "0";
BA_ "Confidence" SG_ 801 VCFRONT_battSensorIrrational 0;
BA_ "Confidence" SG_ 801 VCFRONT_ptSensorIrrational 0;
BA_ "Confidence" SG_ 801 VCFRONT_sensorsCounter 0;
BA_ "Confidence" SG_ 801 VCFRONT_sensorsChecksum 0;
BA_ "Confidence" SG_ 1349 VCFRONT_systemStatusMuxIndex 1;
BA_ "Confidence" SG_ 1349 VCFRONT_systemStatusCounter 0;
BA_ "Confidence" SG_ 1349 VCFRONT_systemStatusChecksum 0;
BA_ "Confidence" SG_ 1349 VCFRONT_loadShedReason 0;
BA_ "Confidence" SG_ 1349 VCFRONT_VCRightEFuseLoadShedStag 0;
BA_ "SystemSignalLongSymbol" SG_ 1349 VCFRONT_VCRightEFuseLoadShedStag "VCFRONT_VCRightEFuseLoadShedStage";
BA_ "Confidence" SG_ 1349 VCFRONT_VCLeftEFuseLoadShedStage 0;
BA_ "Confidence" SG_ 1349 VCFRONT_DCDCSaturationLoadShedSt 0;
BA_ "SystemSignalLongSymbol" SG_ 1349 VCFRONT_DCDCSaturationLoadShedSt "VCFRONT_DCDCSaturationLoadShedStage";
BA_ "Confidence" SG_ 1349 VCFRONT_vehicleLoadShedStage 0;
BA_ "Confidence" SG_ 1349 VCFRONT_HVFaultVehicleLoadShedRe 0;
BA_ "SystemSignalLongSymbol" SG_ 1349 VCFRONT_HVFaultVehicleLoadShedRe "VCFRONT_HVFaultVehicleLoadShedRequest";
BA_ "Confidence" SG_ 1349 VCFRONT_postCrashVehicleLoadShed 0;
BA_ "SystemSignalLongSymbol" SG_ 1349 VCFRONT_postCrashVehicleLoadShed "VCFRONT_postCrashVehicleLoadShedActive";
BA_ "Confidence" SG_ 1349 VCFRONT_HVFaultVehicleLoadShedAc 0;
BA_ "SystemSignalLongSymbol" SG_ 1349 VCFRONT_HVFaultVehicleLoadShedAc "VCFRONT_HVFaultVehicleLoadShedActive";
BA_ "Confidence" SG_ 1349 VCFRONT_factoryVehicleLoadShedAc 0;
BA_ "SystemSignalLongSymbol" SG_ 1349 VCFRONT_factoryVehicleLoadShedAc "VCFRONT_factoryVehicleLoadShedActive";
BA_ "Confidence" SG_ 1349 VCFRONT_anyVehicleLoadShedActive 0;
BA_ "Confidence" SG_ 1349 VCFRONT_DIVehLoadShedActive 0;
BA_ "Confidence" SG_ 1349 VCFRONT_HVFaultLoadShedStateDBG 0;
BA_ "Confidence" SG_ 1349 VCFRONT_LVUnhealthyVehicleLoadSh 0;
BA_ "SystemSignalLongSymbol" SG_ 1349 VCFRONT_LVUnhealthyVehicleLoadSh "VCFRONT_LVUnhealthyVehicleLoadShedActive";
BA_ "Confidence" SG_ 1349 VCFRONT_loadShedStsCondenserFan 0;
BA_ "Confidence" SG_ 1349 VCFRONT_loadShedStsPTPump 0;
BA_ "Confidence" SG_ 1349 VCFRONT_loadShedMCUAudio 0;
BA_ "Confidence" SG_ 1349 VCFRONT_loadShedHVDownTriggerDBG 0;
BA_ "Confidence" SG_ 1349 VCFRONT_loadShedPCSSatTriggerDBG 0;
BA_ "Confidence" SG_ 1349 VCFRONT_loadShedStsBatteryPump 0;
BA_ "Confidence" SG_ 1349 VCFRONT_loadShedStsAPGlassHeater 0;
BA_ "Confidence" SG_ 1349 VCFRONT_loadShedStsMCUGraphics 0;
BA_ "Confidence" SG_ 1349 VCFRONT_IBSCurrentRMS_loadShed 0;
BA_ "Confidence" SG_ 1349 VCFRONT_loadShedAhLeakyBktCntDBG 0;
BA_ "Confidence" SG_ 1349 VCFRONT_loadShedPcs 0;
BA_ "Confidence" SG_ 1349 VCFRONT_loadShedGTWDownstrmRails 0;
BA_ "Confidence" SG_ 1349 VCFRONT_loadShedPCSMIATriggerDBG 0;
BA_ "Confidence" SG_ 1349 VCFRONT_loadShedTAS 0;
BA_ "Confidence" SG_ 1349 VCFRONT_loadShedBackStopBktCntDB 0;
BA_ "SystemSignalLongSymbol" SG_ 1349 VCFRONT_loadShedBackStopBktCntDB "VCFRONT_loadShedBackStopBktCntDBG";
BA_ "Confidence" SG_ 1349 VCFRONT_loadShedPCSLeakyBktCtDBG 0;
BA_ "Confidence" SG_ 1349 VCFRONT_loadShedUI 0;
BA_ "Confidence" SG_ 1349 VCFRONT_loadShedAutoPilot 0;
BA_ "Confidence" SG_ 929 VCFRONT_vehicleStatusMuxIndex 1;
BA_ "Confidence" SG_ 929 VCFRONT_vehicleStatusCounter 0;
BA_ "Confidence" SG_ 929 VCFRONT_vehicleStatusChecksum 0;
BA_ "Confidence" SG_ 929 VCFRONT_preconditionRequest 0;
BA_ "Confidence" SG_ 929 VCFRONT_APGlassHeaterState 0;
BA_ "GenSigSNA" SG_ 929 VCFRONT_APGlassHeaterState "0";
BA_ "Confidence" SG_ 929 VCFRONT_thermalSystemType 0;
BA_ "GenSigSNA" SG_ 929 VCFRONT_thermalSystemType "1";
BA_ "Confidence" SG_ 929 VCFRONT_standbySupplySupported 0;
BA_ "Confidence" SG_ 929 VCFRONT_driverPresent 0;
BA_ "Confidence" SG_ 929 VCFRONT_passengerPresent 0;
BA_ "Confidence" SG_ 929 VCFRONT_accPlusAvailable 0;
BA_ "Confidence" SG_ 929 VCFRONT_diPowerOnState 0;
BA_ "Confidence" SG_ 929 VCFRONT_12vStatusForDrive 0;
BA_ "Confidence" SG_ 929 VCFRONT_dcr12VMilliOhms 0;
BA_ "Confidence" SG_ 929 VC_userPresenceState 0;
BA_ "Confidence" SG_ 929 VCFRONT_factoryLimitsOverrideOk 0;
BA_ "Confidence" SG_ 929 VCFRONT_ota12VSupportRequest 0;
BA_ "Confidence" SG_ 929 VCFRONT_driverBuckleStatus 0;
BA_ "Confidence" SG_ 929 VCFRONT_driverDoorStatus 0;
BA_ "Confidence" SG_ 929 VCFRONT_driverUnbuckled 0;
BA_ "GenSigSNA" SG_ 929 VCFRONT_driverUnbuckled "2";
BA_ "Confidence" SG_ 929 VCFRONT_passengerUnbuckled 0;
BA_ "GenSigSNA" SG_ 929 VCFRONT_passengerUnbuckled "2";
BA_ "Confidence" SG_ 929 VCFRONT_2RowLeftUnbuckled 0;
BA_ "GenSigSNA" SG_ 929 VCFRONT_2RowLeftUnbuckled "2";
BA_ "Confidence" SG_ 929 VCFRONT_2RowCenterUnbuckled 0;
BA_ "GenSigSNA" SG_ 929 VCFRONT_2RowCenterUnbuckled "2";
BA_ "Confidence" SG_ 929 VCFRONT_2RowRightUnbuckled 0;
BA_ "GenSigSNA" SG_ 929 VCFRONT_2RowRightUnbuckled "2";
BA_ "Confidence" SG_ 929 VCFRONT_pcsEFuseVoltage 0;
BA_ "GenSigSNA" SG_ 929 VCFRONT_pcsEFuseVoltage "1023";
BA_ "Confidence" SG_ 929 VCFRONT_bmsHvChargeEnable 0;
BA_ "Confidence" SG_ 929 VCFRONT_3RowLeftUnbuckled 0;
BA_ "GenSigSNA" SG_ 929 VCFRONT_3RowLeftUnbuckled "2";
BA_ "Confidence" SG_ 929 VCFRONT_3RowRightUnbuckled 0;
BA_ "GenSigSNA" SG_ 929 VCFRONT_3RowRightUnbuckled "2";
BA_ "Confidence" SG_ 929 VCFRONT_maxBattHeatRejection 0;
BA_ "Confidence" SG_ 929 VCFRONT_hvacReqBattCoolOutTemp 0;
BA_ "Confidence" SG_ 929 VCFRONT_PCSCurrent 0;
BA_ "Confidence" SG_ 929 VCFRONT_refSystemNominal 0;
BA_ "Confidence" SG_ 929 VCFRONT_driverEnteredCabinEstima 0;
BA_ "SystemSignalLongSymbol" SG_ 929 VCFRONT_driverEnteredCabinEstima "VCFRONT_driverEnteredCabinEstimateDBG";
BA_ "Confidence" SG_ 929 VCFRONT_anySWEFuseActive 0;
BA_ "Confidence" SG_ 929 VCFRONT_hpBattHeatingPowerTrgt 0;
BA_ "Confidence" SG_ 258 VCLEFT_doorClosureStatusFront 0;
BA_ "GenSigSNA" SG_ 258 VCLEFT_doorClosureStatusFront "0";
BA_ "Confidence" SG_ 258 VCLEFT_doorClosureStatusRear 0;
BA_ "GenSigSNA" SG_ 258 VCLEFT_doorClosureStatusRear "0";
BA_ "Confidence" SG_ 258 VCLEFT_frontLatchSwitch 0;
BA_ "Confidence" SG_ 258 VCLEFT_rearLatchSwitch 0;
BA_ "Confidence" SG_ 258 VCLEFT_frontHandlePulled 0;
BA_ "Confidence" SG_ 258 VCLEFT_rearHandlePulled 0;
BA_ "Confidence" SG_ 258 VCLEFT_frontRelActuatorSwitch 0;
BA_ "Confidence" SG_ 258 VCLEFT_rearRelActuatorSwitch 0;
BA_ "Confidence" SG_ 258 VCLEFT_frontLatchStatus 0;
BA_ "GenSigSNA" SG_ 258 VCLEFT_frontLatchStatus "0";
BA_ "Confidence" SG_ 258 VCLEFT_rearLatchStatus 0;
BA_ "GenSigSNA" SG_ 258 VCLEFT_rearLatchStatus "0";
BA_ "Confidence" SG_ 258 VCLEFT_lastDoorReqSourceFront 0;
BA_ "Confidence" SG_ 258 VCLEFT_lastDoorReqSourceRear 0;
BA_ "Confidence" SG_ 258 VCLEFT_frontIntSwitchFaulted 0;
BA_ "Confidence" SG_ 258 VCLEFT_rearIntSwitchFaulted 0;
BA_ "Confidence" SG_ 258 VCLEFT_frontIntSwitchPressed 0;
BA_ "Confidence" SG_ 258 VCLEFT_rearIntSwitchPressed 0;
BA_ "Confidence" SG_ 258 VCLEFT_mirrorTiltXPosition 0;
BA_ "Confidence" SG_ 258 VCLEFT_mirrorTiltYPosition 0;
BA_ "Confidence" SG_ 258 VCLEFT_mirrorState 0;
BA_ "Confidence" SG_ 258 VCLEFT_mirrorFoldState 0;
BA_ "Confidence" SG_ 258 VCLEFT_mirrorRecallState 0;
BA_ "Confidence" SG_ 258 VCLEFT_mirrorHeatState 0;
BA_ "GenSigSNA" SG_ 258 VCLEFT_mirrorHeatState "0";
BA_ "Confidence" SG_ 258 VCLEFT_rearHandlePulledPersist 0;
BA_ "Confidence" SG_ 258 VCLEFT_frontHandlePulledPersist 0;
BA_ "Confidence" SG_ 258 VCLEFT_mirrorDipped 0;
BA_ "Confidence" SG_ 995 VCRIGHT_brakeLightStatus 0;
BA_ "GenSigSNA" SG_ 995 VCRIGHT_brakeLightStatus "3";
BA_ "Confidence" SG_ 995 VCRIGHT_tailLightStatus 0;
BA_ "GenSigSNA" SG_ 995 VCRIGHT_tailLightStatus "3";
BA_ "Confidence" SG_ 995 VCRIGHT_turnSignalStatus 0;
BA_ "GenSigSNA" SG_ 995 VCRIGHT_turnSignalStatus "3";
BA_ "Confidence" SG_ 995 VCRIGHT_reverseLightStatus 0;
BA_ "GenSigSNA" SG_ 995 VCRIGHT_reverseLightStatus "3";
BA_ "Confidence" SG_ 995 VCRIGHT_rearFogLightStatus 0;
BA_ "GenSigSNA" SG_ 995 VCRIGHT_rearFogLightStatus "3";
BA_ "Confidence" SG_ 995 VCRIGHT_leftInteriorTrunkLightRe 0;
BA_ "SystemSignalLongSymbol" SG_ 995 VCRIGHT_leftInteriorTrunkLightRe "VCRIGHT_leftInteriorTrunkLightReq";
BA_ "Confidence" SG_ 995 VCRIGHT_audioCurrentSpikeDetecte 0;
BA_ "SystemSignalLongSymbol" SG_ 995 VCRIGHT_audioCurrentSpikeDetecte "VCRIGHT_audioCurrentSpikeDetected";
BA_ "Confidence" SG_ 1066 VCSEC_TPMSSensorState0 0;
BA_ "Confidence" SG_ 1066 VCSEC_TPMSRSSI0 0;
BA_ "Confidence" SG_ 1066 VCSEC_TPMSConnectionTypeCurrent0 0;
BA_ "Confidence" SG_ 1066 VCSEC_TPMSConnectionTypeDesired0 0;
BA_ "Confidence" SG_ 1066 VCSEC_TPMSSensorState1 0;
BA_ "Confidence" SG_ 1066 VCSEC_TPMSRSSI1 0;
BA_ "Confidence" SG_ 1066 VCSEC_TPMSConnectionTypeCurrent1 0;
BA_ "Confidence" SG_ 1066 VCSEC_TPMSConnectionTypeDesired1 0;
BA_ "Confidence" SG_ 1066 VCSEC_TPMSSensorState2 0;
BA_ "Confidence" SG_ 1066 VCSEC_TPMSRSSI2 0;
BA_ "Confidence" SG_ 1066 VCSEC_TPMSConnectionTypeCurrent2 0;
BA_ "Confidence" SG_ 1066 VCSEC_TPMSConnectionTypeDesired2 0;
BA_ "Confidence" SG_ 1066 VCSEC_TPMSSensorState3 0;
BA_ "Confidence" SG_ 1066 VCSEC_TPMSRSSI3 0;
BA_ "Confidence" SG_ 1066 VCSEC_TPMSConnectionTypeCurrent3 0;
BA_ "Confidence" SG_ 1066 VCSEC_TPMSConnectionTypeDesired3 0;
BA_ "Confidence" SG_ 1066 VCSEC_TPMSSensorPresence0 0;
BA_ "Confidence" SG_ 1066 VCSEC_TPMSSensorPresence1 0;
BA_ "Confidence" SG_ 1066 VCSEC_TPMSSensorPresence2 0;
BA_ "Confidence" SG_ 1066 VCSEC_TPMSSensorPresence3 0;
BA_ "Confidence" SG_ 1817 VCSEC_debug100msIndex 1;
BA_ "Confidence" SG_ 1817 VCSEC_walkAwayLockKeyState 0;
BA_ "Confidence" SG_ 1817 VCSEC_thresholdOffsetVersion 0;
BA_ "Confidence" SG_ 1817 VCSEC_walkAwayLockState 0;
BA_ "Confidence" SG_ 1817 VCSEC_rssi0WLEntry 0;
BA_ "Confidence" SG_ 1817 VCSEC_endpointLayout 0;
BA_ "Confidence" SG_ 1817 VCSEC_rssi1WLEntry 0;
BA_ "Confidence" SG_ 1817 VCSEC_rssi2WLEntry 0;
BA_ "Confidence" SG_ 1817 VCSEC_walkUpUnlockState 0;
BA_ "Confidence" SG_ 1817 VCSEC_algoHighThreshLeft 0;
BA_ "Confidence" SG_ 1817 VCSEC_algoHighThreshRight 0;
BA_ "Confidence" SG_ 1817 VCSEC_algoHighThreshCenter 0;
BA_ "Confidence" SG_ 1817 VCSEC_pollingReason 0;
BA_ "Confidence" SG_ 1817 VCSEC_numberOfPubKeysOnWhitelist 0;
BA_ "Confidence" SG_ 1817 VCSEC_thermalDetectState 0;
BA_ "Confidence" SG_ 1817 VCSEC_chargeHandleMitigationActi 0;
BA_ "SystemSignalLongSymbol" SG_ 1817 VCSEC_chargeHandleMitigationActi "VCSEC_chargeHandleMitigationActive";
BA_ "Confidence" SG_ 1817 VCSEC_device0Offset 0;
BA_ "Confidence" SG_ 1817 VCSEC_device1Offset 0;
BA_ "Confidence" SG_ 1817 VCSEC_device2Offset 0;
VAL_ 594 BMS_powerLimitsState 1 "POWER_CALCULATED_FOR_DRIVE" 0 "POWER_NOT_CALCULATED_FOR_DRIVE" ;
VAL_ 754 BMS_nmKeepAwakeReason 8 "BMS_KEEPAWAKE_REASON_OTA" 7 "BMS_KEEPAWAKE_REASON_PRECONDITIONING" 6 "BMS_KEEPAWAKE_REASON_CP_ACTIVE" 5 "BMS_KEEPAWAKE_REASON_BMS_ACTIVE" 4 "BMS_KEEPAWAKE_REASON_HVP_ACTIVE" 3 "BMS_KEEPAWAKE_REASON_FC_CTR_CLEANING" 2 "BMS_KEEPAWAKE_REASON_CRITICAL_ALERT" 1 "BMS_KEEPAWAKE_REASON_CTRS_CLOSED" 0 "BMS_KEEPAWAKE_REASON_NONE_SNA" ;
VAL_ 754 BMS_nmWakeUpReason 4 "BMS_WAKEUP_REASON_CRITICALALERT" 3 "BMS_WAKEUP_REASON_WANTTOCHARGE" 2 "BMS_WAKEUP_REASON_CAN_HVS" 1 "BMS_WAKEUP_REASON_CAN_VEH" 0 "BMS_WAKEUP_REASON_NONE" ;
VAL_ 812 CC_logIndex 13 "Mux13" 12 "Mux12" 11 "Mux11" 10 "Mux10" 4 "Mux4" 3 "Mux3" 2 "Mux2" 1 "Mux1" 0 "Mux0" ;
VAL_ 812 CC_activeConnectorID 255 "SNA" ;
VAL_ 812 CC_temperature1 127 "SNA" ;
VAL_ 812 CC_temperature2 127 "SNA" ;
VAL_ 812 CC_temperature3 127 "SNA" ;
VAL_ 812 CC_contactor1Closed 3 "CC_CONTACTOR_SNA" 1 "CC_CONTACTOR_CLOSED" 0 "CC_CONTACTOR_OPEN" ;
VAL_ 812 CC_contactor2Closed 3 "CC_CONTACTOR_SNA" 1 "CC_CONTACTOR_CLOSED" 0 "CC_CONTACTOR_OPEN" ;
VAL_ 812 CC_temperature4 127 "SNA" ;
VAL_ 812 CC_conn1Current 255 "SNA" ;
VAL_ 812 CC_conn2Current 255 "SNA" ;
VAL_ 812 CC_conn3Current 255 "SNA" ;
VAL_ 812 CC_conn4Current 255 "SNA" ;
VAL_ 669 CP_evseDeratingReason 31 "EVSE_DERATING_INVALID" 2 "EVSE_DERATING_POST_SYSTEM_FAULT" 1 "EVSE_DERATING_CABLE_TEMP_FOLDBACK" 0 "EVSE_DERATING_NONE" ;
VAL_ 1885 CP_loggingFastSelect 6 "6" 5 "5" 4 "4" 3 "3" 2 "2" 1 "1" 0 "0" ;
VAL_ 1885 CP_chargeCablePresent 1 "CABLE_PRESENT" 0 "CABLE_NOT_PRESENT" ;
VAL_ 1885 CP_UHF_controlState 10 "CP_UHF_FAULT" 9 "CP_UHF_SLEEP" 8 "CP_UHF_HANDLE_FOUND" 7 "CP_UHF_READ_RXFIFO" 6 "CP_UHF_CHECK_RX" 5 "CP_UHF_RX" 4 "CP_UHF_PREPARE_RX" 3 "CP_UHF_CALIBRATE" 2 "CP_UHF_IDLE" 1 "CP_UHF_CONFIG" 0 "CP_UHF_INIT" ;
VAL_ 1885 CP_doorOpenRequest 8 "CPD_OPEN_REQ_NUM" 7 "CPD_OPEN_REQ_CABLE_RECONNECTED" 6 "CPD_OPEN_REQ_VCFRONT" 5 "CPD_OPEN_REQ_CLOSING_FAILED" 4 "CPD_OPEN_REQ_PUSH_TO_OPEN" 3 "CPD_OPEN_REQ_UHF" 2 "CPD_OPEN_REQ_SEC" 1 "CPD_OPEN_REQ_UI" 0 "CPD_OPEN_REQ_NONE" ;
VAL_ 1885 CP_doorOpenEndOfDriveReason 7 "CP_STOP_DRIVE_REASON_OVERCURRENT" 6 "CP_STOP_DRIVE_REASON_REQ_OVERRIDE" 5 "CP_STOP_DRIVE_REASON_ABSOLUTE_TIMEOUT" 4 "CP_STOP_DRIVE_REASON_MAX_TARGET_V" 3 "CP_STOP_DRIVE_REASON_REACHED_STOP" 2 "CP_STOP_DRIVE_REASON_STOPPED_MOVING_TIMEOUT" 1 "CP_STOP_DRIVE_REASON_STALLED" 0 "CP_STOP_DRIVE_REASON_NONE" ;
VAL_ 1885 CP_doorCloseEndOfDriveReason 7 "CP_STOP_DRIVE_REASON_OVERCURRENT" 6 "CP_STOP_DRIVE_REASON_REQ_OVERRIDE" 5 "CP_STOP_DRIVE_REASON_ABSOLUTE_TIMEOUT" 4 "CP_STOP_DRIVE_REASON_MAX_TARGET_V" 3 "CP_STOP_DRIVE_REASON_REACHED_STOP" 2 "CP_STOP_DRIVE_REASON_STOPPED_MOVING_TIMEOUT" 1 "CP_STOP_DRIVE_REASON_STALLED" 0 "CP_STOP_DRIVE_REASON_NONE" ;
VAL_ 1885 CP_doorCloseRequest 16 "CPD_CLOSE_REQ_NUM" 15 "CPD_CLOSE_REQ_COVER_OPEN" 14 "CPD_CLOSE_REQ_VCFRONT" 13 "CPD_CLOSE_REQ_OPEN_ON_WAKE" 12 "CPD_CLOSE_REQ_SENSOR_COMMS_RECOVERED" 11 "CPD_CLOSE_REQ_SENSOR_MISMATCH" 10 "CPD_CLOSE_REQ_INITIAL_CINCH" 9 "CPD_CLOSE_REQ_OPENED_IN_DRIVE_STATE" 8 "CPD_CLOSE_REQ_ENTER_DRIVE" 7 "CPD_CLOSE_REQ_FAULT_LINE" 6 "CPD_CLOSE_REQ_CAR_WASH" 5 "CPD_CLOSE_REQ_PUSH_TO_CLOSE" 4 "CPD_CLOSE_REQ_SEC" 3 "CPD_CLOSE_REQ_UI" 2 "CPD_CLOSE_REQ_DOOR_OPEN_TIMEOUT" 1 "CPD_CLOSE_REQ_CABLE_UNPLUGGED" 0 "CPD_CLOSE_REQ_NONE" ;
VAL_ 1885 CP_latchDisengagingStopReason 7 "CP_STOP_DRIVE_REASON_OVERCURRENT" 6 "CP_STOP_DRIVE_REASON_REQ_OVERRIDE" 5 "CP_STOP_DRIVE_REASON_ABSOLUTE_TIMEOUT" 4 "CP_STOP_DRIVE_REASON_MAX_TARGET_V" 3 "CP_STOP_DRIVE_REASON_REACHED_STOP" 2 "CP_STOP_DRIVE_REASON_STOPPED_MOVING_TIMEOUT" 1 "CP_STOP_DRIVE_REASON_STALLED" 0 "CP_STOP_DRIVE_REASON_NONE" ;
VAL_ 1885 CP_latchEngagingStopReason 7 "CP_STOP_DRIVE_REASON_OVERCURRENT" 6 "CP_STOP_DRIVE_REASON_REQ_OVERRIDE" 5 "CP_STOP_DRIVE_REASON_ABSOLUTE_TIMEOUT" 4 "CP_STOP_DRIVE_REASON_MAX_TARGET_V" 3 "CP_STOP_DRIVE_REASON_REACHED_STOP" 2 "CP_STOP_DRIVE_REASON_STOPPED_MOVING_TIMEOUT" 1 "CP_STOP_DRIVE_REASON_STALLED" 0 "CP_STOP_DRIVE_REASON_NONE" ;
VAL_ 1885 CP_doorIdDetectionState 2 "DOOR_ID_VALID" 1 "DOOR_ID_INVALID" 0 "DOOR_ID_UNKNOWN_SNA" ;
VAL_ 1885 CP_doorIdDetectedBin 3 "DOOR_ID_BIN_OPAL" 2 "DOOR_ID_BIN_HMC" 1 "DOOR_ID_BIN_NMB" 0 "DOOR_ID_BIN_UNKNOWN" ;
VAL_ 989 CP_loggingSlowSelect 8 "8" 7 "7" 6 "6" 5 "5" 4 "4" 3 "3" 2 "2" 1 "1" 0 "0" ;
VAL_ 989 CP_inlet1HarnessIdState 2 "HARNESS_PEDIGREE_VALID" 1 "HARNESS_PEDIGREE_INVALID" 0 "HARNESS_PEDIGREE_UNKNOWN_SNA" ;
VAL_ 989 CP_inlet2HarnessIdState 2 "HARNESS_PEDIGREE_VALID" 1 "HARNESS_PEDIGREE_INVALID" 0 "HARNESS_PEDIGREE_UNKNOWN_SNA" ;
VAL_ 989 CP_inletHeaterState 3 "INLET_HEATER_FAULTED" 2 "INLET_HEATER_ENABLED_LOWTEMP" 1 "INLET_HEATER_ENABLED_HIGHTEMP" 0 "INLET_HEATER_DISABLED" ;
VAL_ 989 CP_doorOpenLimiterMaxRequestType 8 "CPD_OPEN_REQ_NUM" 7 "CPD_OPEN_REQ_CABLE_RECONNECTED" 6 "CPD_OPEN_REQ_VCFRONT" 5 "CPD_OPEN_REQ_CLOSING_FAILED" 4 "CPD_OPEN_REQ_PUSH_TO_OPEN" 3 "CPD_OPEN_REQ_UHF" 2 "CPD_OPEN_REQ_SEC" 1 "CPD_OPEN_REQ_UI" 0 "CPD_OPEN_REQ_NONE" ;
VAL_ 989 CP_doorCloseLimiterMaxRequestTyp 16 "CPD_CLOSE_REQ_NUM" 15 "CPD_CLOSE_REQ_COVER_OPEN" 14 "CPD_CLOSE_REQ_VCFRONT" 13 "CPD_CLOSE_REQ_OPEN_ON_WAKE" 12 "CPD_CLOSE_REQ_SENSOR_COMMS_RECOVERED" 11 "CPD_CLOSE_REQ_SENSOR_MISMATCH" 10 "CPD_CLOSE_REQ_INITIAL_CINCH" 9 "CPD_CLOSE_REQ_OPENED_IN_DRIVE_STATE" 8 "CPD_CLOSE_REQ_ENTER_DRIVE" 7 "CPD_CLOSE_REQ_FAULT_LINE" 6 "CPD_CLOSE_REQ_CAR_WASH" 5 "CPD_CLOSE_REQ_PUSH_TO_CLOSE" 4 "CPD_CLOSE_REQ_SEC" 3 "CPD_CLOSE_REQ_UI" 2 "CPD_CLOSE_REQ_DOOR_OPEN_TIMEOUT" 1 "CPD_CLOSE_REQ_CABLE_UNPLUGGED" 0 "CPD_CLOSE_REQ_NONE" ;
VAL_ 893 CP_thermalStatusSelect 1 "1" 0 "0" ;
VAL_ 893 CP_pinTemp4Velocity 511 "SNA" ;
VAL_ 2024 EPBR_infoIndex 255 "END" 41 "SUBCOMPONENT14" 40 "SUBCOMPONENT13" 39 "SUBCOMPONENT12" 38 "SUBCOMPONENT11" 37 "SUBCOMPONENT10" 36 "SUBCOMPONENT9" 35 "SUBCOMPONENT8" 34 "SUBCOMPONENT7" 33 "SUBCOMPONENT6" 32 "SUBCOMPONENT5" 31 "SUBCOMPONENT4" 24 "SUBCOMPONENT3" 23 "SUBCOMPONENT2" 20 "UDS_PROTOCOL_BOOTCRC" 19 "VERSION_DEPRECATED" 18 "BOOTLOADER_GITHASH" 17 "APP_GITHASH" 16 "SUBCOMPONENT1" 15 "BOOTLOADER_CRC" 14 "BOOTLOADER_SVN" 13 "APP_CRC" 11 "PCBAID_ASSYID_USAGEID" 10 "BUILD_HWID_COMPONENTID" 9 "DEPRECATED_9" 8 "DEPRECATED_8" 7 "DEPRECATED_7" 6 "DEPRECATED_6" 5 "DEPRECATED_5" 4 "DEPRECATED_4" 3 "DEPRECATED_3" 2 "DEPRECATED_2" 1 "DEPRECATED_1" 0 "DEPRECATED_0" ;
VAL_ 2024 EPBR_infoBuildType 4 "INFO_MFG_BUILD" 3 "INFO_TRACEABLE_CI_BUILD" 2 "INFO_LOCAL_BUILD" 1 "INFO_PLATFORM_BUILD" 0 "INFO_UNKNOWN_BUILD" ;
VAL_ 2024 EPBR_infoAssemblyId 255 "ASSEMBLY_SNA" 1 "ASSEMBLY1" ;
VAL_ 1914 HVP_log1HzIndex 1 "Mux1" 0 "Mux0" ;
VAL_ 1914 HVP_bmbAsicType 3 "BQ796xx" 2 "ADBMS6830" 1 "LTC831" 0 "UNKNOWN" ;
VAL_ 1914 HVP_shuntCurrentAuxLog 8388000 "PACK_CURRENT_SNA" ;
VAL_ 1914 HVP_pyroSquibResistance 65535 "SNA" ;
VAL_ 1914 HVP_hvilCalType 2 "CAN" 1 "LV" 0 "UNKNOWN" ;
VAL_ 664 ICR_sensorMode 15 "ICR_SENSOR_INTERFACE_MODE_ERROR" 7 "ICR_SENSOR_INTERFACE_MODE_LPM_TEST" 6 "ICR_SENSOR_INTERFACE_MODE_OCCUPANCY_DETECTION" 5 "ICR_SENSOR_INTERFACE_MODE_HPM_TEST" 4 "ICR_SENSOR_INTERFACE_MODE_CALIBRATION" 3 "ICR_SENSOR_INTERFACE_MODE_CW" 2 "ICR_SENSOR_MODE_END_OF_LINE_TEST" 1 "ICR_SENSOR_MODE_INTRUSTION" 0 "ICR_SENSOR_MODE_SENSOR_STOPPED" ;
VAL_ 664 ICR_blocked 2 "ICR_BLOCKED_TRUE" 1 "ICR_BLOCKED_FALSE" 0 "ICR_BLOCKED_SNA" ;
VAL_ 664 ICR_algoVersion 37 "ICR_ALGO_VERSION_FUTURE_RELEASE_37" 36 "ICR_ALGO_VERSION_v06112025" 35 "ICR_ALGO_VERSION_v04232025" 34 "ICR_ALGO_VERSION_v03192025" 33 "ICR_ALGO_VERSION_v02142025" 32 "ICR_ALGO_VERSION_v01222025" 31 "ICR_ALGO_VERSION_v10072024" 30 "ICR_ALGO_VERSION_v08282024" 29 "ICR_ALGO_VERSION_v07172024" 28 "ICR_ALGO_VERSION_v06122024" 27 "ICR_ALGO_VERSION_v04242024" 26 "ICR_ALGO_VERSION_v03142024" 25 "ICR_ALGO_VERSION_v01312024" 24 "ICR_ALGO_VERSION_v12192023" 23 "ICR_ALGO_VERSION_v10252023" 22 "ICR_ALGO_VERSION_v10112023" 21 "ICR_ALGO_VERSION_v09222023" 20 "ICR_ALGO_VERSION_V08302023" 19 "ICR_ALGO_VERSION_V07172023" 18 "ICR_ALGO_VERSION_V06152023" 17 "ICR_ALGO_VERSION_V06072023" 16 "ICR_ALGO_VERSION_V05192023" 15 "ICR_ALGO_VERSION_V04262023" 14 "ICR_ALGO_VERSION_V1222" 13 "ICR_ALGO_VERSION_V1125" 12 "ICR_ALGO_VERSION_V1118" 11 "ICR_ALGO_VERSION_V1103" 10 "ICR_ALGO_VERSION_V1013" 9 "ICR_ALGO_VERSION_V1006" 8 "ICR_ALGO_VERSION_V927" 7 "ICR_ALGO_VERSION_V902" 6 "ICR_ALGO_VERSION_V826" 5 "ICR_ALGO_VERSION_V803" 4 "ICR_ALGO_VERSION_V715" 3 "ICR_ALGO_VERSION_V711" 2 "ICR_ALGO_VERSION_V204" 1 "ICR_ALGO_VERSION_EXPERIMENTAL" 0 "ICR_ALGO_VERSION_NONE" ;
VAL_ 664 ICR_intrusionStatus 2 "INSTRUSION_STATUS_INTRUSION_DETECTED" 1 "INSTRUSION_STATUS_NONE" 0 "INSTRUSION_STATUS_UNKNOWN" ;
VAL_ 676 PCS_chgPhATemp -1023 "SNA" ;
VAL_ 676 PCS_chgPhBTemp -1023 "SNA" ;
VAL_ 676 PCS_chgPhCTemp -1023 "SNA" ;
VAL_ 676 PCS_dcdcTemp -1023 "SNA" ;
VAL_ 676 PCS_ambientTemp -1023 "SNA" ;
VAL_ 676 PCS_dcdcBusbarTemp 511 "SNA" ;
VAL_ 819 UI_acChargeCurrentLimit 127 "SNA" ;
VAL_ 819 UI_chargePortLatchRequest 2 "UI_LATCH_REQUEST_DISENGAGE" 1 "UI_LATCH_REQUEST_ENGAGE" 0 "UI_LATCH_REQUEST_NONE" ;
VAL_ 819 UI_cpInletHeaterRequest 2 "HEATER_MANUAL_OVERRIDE" 1 "HEATER_AUTO" 0 "HEATER_OFF" ;
VAL_ 1119 VCBATT1_LVSelfTestsIndex 1 "STATES" 0 "ORCHESTRATOR" ;
VAL_ 1119 VCBATT1_battDomainOvercurrentSel 2 "VC_SELF_TEST_RESULT_PASSED" 1 "VC_SELF_TEST_RESULT_FAILED" 0 "VC_SELF_TEST_RESULT_INVALID" ;
VAL_ 1119 VCBATT1_battDomainOvercurre_0001 4 "VC_SELF_TEST_STATE_SNA" 3 "VC_SELF_TEST_STATE_NEW_RESULT" 2 "VC_SELF_TEST_STATE_RUNNING" 1 "VC_SELF_TEST_STATE_PENDING" 0 "VC_SELF_TEST_STATE_IDLE" ;
VAL_ 1119 VCBATT1_battDomainOvervoltageSel 2 "VC_SELF_TEST_RESULT_PASSED" 1 "VC_SELF_TEST_RESULT_FAILED" 0 "VC_SELF_TEST_RESULT_INVALID" ;
VAL_ 1119 VCBATT1_battDomainOvervolta_0001 4 "VC_SELF_TEST_STATE_SNA" 3 "VC_SELF_TEST_STATE_NEW_RESULT" 2 "VC_SELF_TEST_STATE_RUNNING" 1 "VC_SELF_TEST_STATE_PENDING" 0 "VC_SELF_TEST_STATE_IDLE" ;
VAL_ 1119 VCBATT1_battDomainUndervoltageSe 2 "VC_SELF_TEST_RESULT_PASSED" 1 "VC_SELF_TEST_RESULT_FAILED" 0 "VC_SELF_TEST_RESULT_INVALID" ;
VAL_ 1119 VCBATT1_battDomainUndervolt_0001 4 "VC_SELF_TEST_STATE_SNA" 3 "VC_SELF_TEST_STATE_NEW_RESULT" 2 "VC_SELF_TEST_STATE_RUNNING" 1 "VC_SELF_TEST_STATE_PENDING" 0 "VC_SELF_TEST_STATE_IDLE" ;
VAL_ 1119 VCBATT1_dualPowerLoadsSelfTestRe 2 "VC_SELF_TEST_RESULT_PASSED" 1 "VC_SELF_TEST_RESULT_FAILED" 0 "VC_SELF_TEST_RESULT_INVALID" ;
VAL_ 1119 VCBATT1_dualPowerLoadsSelfTestSt 4 "VC_SELF_TEST_STATE_SNA" 3 "VC_SELF_TEST_STATE_NEW_RESULT" 2 "VC_SELF_TEST_STATE_RUNNING" 1 "VC_SELF_TEST_STATE_PENDING" 0 "VC_SELF_TEST_STATE_IDLE" ;
VAL_ 1119 VCBATT1_vcbattBridgeEFuseASICSel 2 "VC_SELF_TEST_RESULT_PASSED" 1 "VC_SELF_TEST_RESULT_FAILED" 0 "VC_SELF_TEST_RESULT_INVALID" ;
VAL_ 1119 VCBATT1_vcbattBridgeEFuseAS_0001 4 "VC_SELF_TEST_STATE_SNA" 3 "VC_SELF_TEST_STATE_NEW_RESULT" 2 "VC_SELF_TEST_STATE_RUNNING" 1 "VC_SELF_TEST_STATE_PENDING" 0 "VC_SELF_TEST_STATE_IDLE" ;
VAL_ 1119 VCBATT1_uvProtectionState 12 "VC_UV_STATE_DELIBERATELY_TRIPPED" 11 "VC_UV_STATE_TRIPPED" 10 "VC_UV_STATE_ARMED" 9 "VC_UV_STATE_SELF_TEST_CLEAN_UP" 8 "VC_UV_STATE_SELF_TEST_CHECK_STUCK_ON" 7 "VC_UV_STATE_SELF_TEST_CHECK_STUCK_OFF_COMPLETE" 6 "VC_UV_STATE_SELF_TEST_CHECK_STUCK_OFF" 5 "VC_UV_STATE_SELF_TEST_LOADS_GOING_DOWN_COMPLETE" 4 "VC_UV_STATE_SELF_TEST_LOADS_GOING_DOWN" 3 "VC_UV_STATE_SELF_TEST_LOADS_ON" 2 "VC_UV_STATE_SELF_TEST_TURN_ON_LOADS" 1 "VC_UV_STATE_SELF_TEST_SETUP" 0 "VC_UV_STATE_IDLE" ;
VAL_ 1119 VC_selfTestsRunningMode 4 "DISABLED" 3 "REDUCED" 2 "FACTORY_REDUCED" 1 "FACTORY_NORMAL" 0 "NORMAL" ;
VAL_ 801 VCFRONT_tempCoolantBatInlet 1023 "SNA" ;
VAL_ 801 VCFRONT_tempCoolantPTInlet 2047 "SNA" ;
VAL_ 801 VCFRONT_coolantLevel 1 "FILLED" 0 "NOT_OK" ;
VAL_ 801 VCFRONT_brakeFluidLevel 2 "NORMAL" 1 "LOW" 0 "SNA" ;
VAL_ 801 VCFRONT_tempAmbient 0 "SNA" ;
VAL_ 801 VCFRONT_washerFluidLevel 2 "NORMAL" 1 "LOW" 0 "SNA" ;
VAL_ 801 VCFRONT_tempAmbientFiltered 0 "SNA" ;
VAL_ 1349 VCFRONT_systemStatusMuxIndex 2 "LOAD_SHED_STATUSES_AND_COMMANDS" 1 "ACTIVE_LOAD_SHED_REASONS" 0 "SYSTEM_DATA" ;
VAL_ 1349 VCFRONT_loadShedReason 256 "VCFRONT_LOAD_SHED_REASON_LV_HEALTH" 128 "VCFRONT_LOAD_SHED_REASON_PRECHARGE" 64 "VCFRONT_LOAD_SHED_REASON_CUSTOM" 32 "VCFRONT_LOAD_SHED_REASON_FACTORY" 16 "VCFRONT_LOAD_SHED_REASON_HV_FAULT" 8 "VCFRONT_LOAD_SHED_REASON_POST_CRASH" 4 "VCFRONT_LOAD_SHED_REASON_VCRIGHT_EFUSE_PROTECTION" 2 "VCFRONT_LOAD_SHED_REASON_VCLEFT_EFUSE_PROTECTION" 1 "VCFRONT_LOAD_SHED_REASON_DCDC_SATURATION" 0 "VCFRONT_LOAD_SHED_REASON_NONE" ;
VAL_ 1349 VCFRONT_VCRightEFuseLoadShedStag 31 "MAX" 0 "IDLE" ;
VAL_ 1349 VCFRONT_VCLeftEFuseLoadShedStage 31 "MAX" 0 "IDLE" ;
VAL_ 1349 VCFRONT_DCDCSaturationLoadShedSt 31 "MAX" 0 "IDLE" ;
VAL_ 1349 VCFRONT_vehicleLoadShedStage 3 "VEHICLE_LOADSHEDDING_STAGE_3" 2 "VEHICLE_LOADSHEDDING_STAGE_2" 1 "VEHICLE_LOADSHEDDING_STAGE_1" 0 "VEHICLE_LOADSHEDDING_STAGE_IDLE_OR_UNDEFINED" ;
VAL_ 1349 VCFRONT_HVFaultLoadShedStateDBG 3 "HV_FAULT_LOADSHED_SM_STATE_ACTIVE" 2 "HV_FAULT_LOADSHED_SM_STATE_BLOCKED" 1 "HV_FAULT_LOADSHED_SM_STATE_IDLE" 0 "HV_FAULT_LOADSHED_SM_STATE_INIT" ;
VAL_ 929 VCFRONT_vehicleStatusMuxIndex 1 "MUX1" 0 "MUX0" ;
VAL_ 929 VCFRONT_APGlassHeaterState 4 "HEATER_STATE_FAULT" 3 "HEATER_STATE_OFF_UNAVAILABLE" 2 "HEATER_STATE_OFF" 1 "HEATER_STATE_ON" 0 "HEATER_STATE_SNA" ;
VAL_ 929 VCFRONT_thermalSystemType 1 "HEAT_PUMP_THERMAL_SYSTEM" 0 "LEGACY_THERMAL_SYSTEM" ;
VAL_ 929 VCFRONT_diPowerOnState 5 "DI_POWERED_ON_FOR_WINCH" 4 "DI_POWER_GOING_DOWN" 3 "DI_POWERED_ON_FOR_DRIVE" 2 "DI_POWERED_ON_FOR_STATIONARY_HEAT" 1 "DI_POWERED_ON_FOR_SUMMON" 0 "DI_POWERED_OFF" ;
VAL_ 929 VCFRONT_12vStatusForDrive 2 "EXIT_DRIVE_REQUESTED_12V" 1 "READY_FOR_DRIVE_12V" 0 "NOT_READY_FOR_DRIVE_12V" ;
VAL_ 929 VC_userPresenceState 3 "TIMED_OUT" 2 "PRESENT" 1 "NOT_PRESENT" 0 "INIT" ;
VAL_ 929 VCFRONT_driverBuckleStatus 1 "BUCKLED" 0 "UNBUCKLED" ;
VAL_ 929 VCFRONT_driverDoorStatus 1 "DOOR_CLOSED" 0 "DOOR_OPEN" ;
VAL_ 929 VCFRONT_driverUnbuckled 2 "CHIME_SNA" 1 "CHIME_OCCUPIED_AND_UNBUCKLED" 0 "CHIME_NONE" ;
VAL_ 929 VCFRONT_passengerUnbuckled 2 "CHIME_SNA" 1 "CHIME_OCCUPIED_AND_UNBUCKLED" 0 "CHIME_NONE" ;
VAL_ 929 VCFRONT_2RowLeftUnbuckled 2 "CHIME_SNA" 1 "CHIME_OCCUPIED_AND_UNBUCKLED" 0 "CHIME_NONE" ;
VAL_ 929 VCFRONT_2RowCenterUnbuckled 2 "CHIME_SNA" 1 "CHIME_OCCUPIED_AND_UNBUCKLED" 0 "CHIME_NONE" ;
VAL_ 929 VCFRONT_2RowRightUnbuckled 2 "CHIME_SNA" 1 "CHIME_OCCUPIED_AND_UNBUCKLED" 0 "CHIME_NONE" ;
VAL_ 929 VCFRONT_pcsEFuseVoltage 1023 "SNA" ;
VAL_ 929 VCFRONT_3RowLeftUnbuckled 2 "CHIME_SNA" 1 "CHIME_OCCUPIED_AND_UNBUCKLED" 0 "CHIME_NONE" ;
VAL_ 929 VCFRONT_3RowRightUnbuckled 2 "CHIME_SNA" 1 "CHIME_OCCUPIED_AND_UNBUCKLED" 0 "CHIME_NONE" ;
VAL_ 258 VCLEFT_doorClosureStatusFront 8 "CLOSURE_STATUS_FAULT" 2 "CLOSURE_STATUS_CLOSED" 1 "CLOSURE_STATUS_OPEN" 0 "CLOSURE_STATUS_SNA" ;
VAL_ 258 VCLEFT_doorClosureStatusRear 8 "CLOSURE_STATUS_FAULT" 2 "CLOSURE_STATUS_CLOSED" 1 "CLOSURE_STATUS_OPEN" 0 "CLOSURE_STATUS_SNA" ;
VAL_ 258 VCLEFT_frontLatchStatus 8 "LATCH_FAULT" 7 "LATCH_DEFAULT" 6 "LATCH_TIMEOUT" 5 "LATCH_AJAR" 4 "LATCH_OPENING" 3 "LATCH_CLOSING" 2 "LATCH_CLOSED" 1 "LATCH_OPENED" 0 "LATCH_SNA" ;
VAL_ 258 VCLEFT_rearLatchStatus 8 "LATCH_FAULT" 7 "LATCH_DEFAULT" 6 "LATCH_TIMEOUT" 5 "LATCH_AJAR" 4 "LATCH_OPENING" 3 "LATCH_CLOSING" 2 "LATCH_CLOSED" 1 "LATCH_OPENED" 0 "LATCH_SNA" ;
VAL_ 258 VCLEFT_lastDoorReqSourceFront 4 "DOOR_REQUEST_SOURCE_ECU" 3 "DOOR_REQUEST_SOURCE_VCSEC" 2 "DOOR_REQUEST_SOURCE_EXTERIOR_HANDLE" 1 "DOOR_REQUEST_SOURCE_INTERIOR_BUTTON" 0 "DOOR_REQUEST_SOURCE_UNKNOWN" ;
VAL_ 258 VCLEFT_lastDoorReqSourceRear 4 "DOOR_REQUEST_SOURCE_ECU" 3 "DOOR_REQUEST_SOURCE_VCSEC" 2 "DOOR_REQUEST_SOURCE_EXTERIOR_HANDLE" 1 "DOOR_REQUEST_SOURCE_INTERIOR_BUTTON" 0 "DOOR_REQUEST_SOURCE_UNKNOWN" ;
VAL_ 258 VCLEFT_mirrorState 5 "MIRROR_STATE_CALIBRATION" 4 "MIRROR_STATE_RECALL" 3 "MIRROR_STATE_FOLD_UNFOLD" 2 "MIRROR_STATE_TILT_Y" 1 "MIRROR_STATE_TILT_X" 0 "MIRROR_STATE_IDLE" ;
VAL_ 258 VCLEFT_mirrorFoldState 4 "MIRROR_FOLD_STATE_UNFOLDING" 3 "MIRROR_FOLD_STATE_FOLDING" 2 "MIRROR_FOLD_STATE_UNFOLDED" 1 "MIRROR_FOLD_STATE_FOLDED" 0 "MIRROR_FOLD_STATE_UNKNOWN" ;
VAL_ 258 VCLEFT_mirrorRecallState 5 "MIRROR_RECALL_STATE_RECALLING_STOPPED" 4 "MIRROR_RECALL_STATE_RECALLING_FAILED" 3 "MIRROR_RECALL_STATE_RECALLING_COMPLETE" 2 "MIRROR_RECALL_STATE_RECALLING_AXIS_2" 1 "MIRROR_RECALL_STATE_RECALLING_AXIS_1" 0 "MIRROR_RECALL_STATE_INIT" ;
VAL_ 258 VCLEFT_mirrorHeatState 4 "HEATER_STATE_FAULT" 3 "HEATER_STATE_OFF_UNAVAILABLE" 2 "HEATER_STATE_OFF" 1 "HEATER_STATE_ON" 0 "HEATER_STATE_SNA" ;
VAL_ 995 VCRIGHT_brakeLightStatus 3 "LIGHT_SNA" 2 "LIGHT_FAULT" 1 "LIGHT_ON" 0 "LIGHT_OFF" ;
VAL_ 995 VCRIGHT_tailLightStatus 3 "LIGHT_SNA" 2 "LIGHT_FAULT" 1 "LIGHT_ON" 0 "LIGHT_OFF" ;
VAL_ 995 VCRIGHT_turnSignalStatus 3 "LIGHT_SNA" 2 "LIGHT_FAULT" 1 "LIGHT_ON" 0 "LIGHT_OFF" ;
VAL_ 995 VCRIGHT_reverseLightStatus 3 "LIGHT_SNA" 2 "LIGHT_FAULT" 1 "LIGHT_ON" 0 "LIGHT_OFF" ;
VAL_ 995 VCRIGHT_rearFogLightStatus 3 "LIGHT_SNA" 2 "LIGHT_FAULT" 1 "LIGHT_ON" 0 "LIGHT_OFF" ;
VAL_ 1066 VCSEC_TPMSSensorState0 5 "SENSOR_WAIT_FOR_NEXT_ADV" 4 "SENSOR_DISCONNECTING" 3 "SENSOR_CONNECTED" 2 "SENSOR_WAIT_FOR_CONN" 1 "SENSOR_WAIT_FOR_ADV" 0 "SENSOR_NOT_PAIRED" ;
VAL_ 1066 VCSEC_TPMSConnectionTypeCurrent0 3 "CONNECTIONTYPE_FAST_SLAVE_LATENCY" 2 "CONNECTIONTYPE_UNKNOWN" 1 "CONNECTIONTYPE_SLOW" 0 "CONNECTIONTYPE_FAST" ;
VAL_ 1066 VCSEC_TPMSConnectionTypeDesired0 3 "CONNECTIONTYPE_FAST_SLAVE_LATENCY" 2 "CONNECTIONTYPE_UNKNOWN" 1 "CONNECTIONTYPE_SLOW" 0 "CONNECTIONTYPE_FAST" ;
VAL_ 1066 VCSEC_TPMSSensorState1 5 "SENSOR_WAIT_FOR_NEXT_ADV" 4 "SENSOR_DISCONNECTING" 3 "SENSOR_CONNECTED" 2 "SENSOR_WAIT_FOR_CONN" 1 "SENSOR_WAIT_FOR_ADV" 0 "SENSOR_NOT_PAIRED" ;
VAL_ 1066 VCSEC_TPMSConnectionTypeCurrent1 3 "CONNECTIONTYPE_FAST_SLAVE_LATENCY" 2 "CONNECTIONTYPE_UNKNOWN" 1 "CONNECTIONTYPE_SLOW" 0 "CONNECTIONTYPE_FAST" ;
VAL_ 1066 VCSEC_TPMSConnectionTypeDesired1 3 "CONNECTIONTYPE_FAST_SLAVE_LATENCY" 2 "CONNECTIONTYPE_UNKNOWN" 1 "CONNECTIONTYPE_SLOW" 0 "CONNECTIONTYPE_FAST" ;
VAL_ 1066 VCSEC_TPMSSensorState2 5 "SENSOR_WAIT_FOR_NEXT_ADV" 4 "SENSOR_DISCONNECTING" 3 "SENSOR_CONNECTED" 2 "SENSOR_WAIT_FOR_CONN" 1 "SENSOR_WAIT_FOR_ADV" 0 "SENSOR_NOT_PAIRED" ;
VAL_ 1066 VCSEC_TPMSConnectionTypeCurrent2 3 "CONNECTIONTYPE_FAST_SLAVE_LATENCY" 2 "CONNECTIONTYPE_UNKNOWN" 1 "CONNECTIONTYPE_SLOW" 0 "CONNECTIONTYPE_FAST" ;
VAL_ 1066 VCSEC_TPMSConnectionTypeDesired2 3 "CONNECTIONTYPE_FAST_SLAVE_LATENCY" 2 "CONNECTIONTYPE_UNKNOWN" 1 "CONNECTIONTYPE_SLOW" 0 "CONNECTIONTYPE_FAST" ;
VAL_ 1066 VCSEC_TPMSSensorState3 5 "SENSOR_WAIT_FOR_NEXT_ADV" 4 "SENSOR_DISCONNECTING" 3 "SENSOR_CONNECTED" 2 "SENSOR_WAIT_FOR_CONN" 1 "SENSOR_WAIT_FOR_ADV" 0 "SENSOR_NOT_PAIRED" ;
VAL_ 1066 VCSEC_TPMSConnectionTypeCurrent3 3 "CONNECTIONTYPE_FAST_SLAVE_LATENCY" 2 "CONNECTIONTYPE_UNKNOWN" 1 "CONNECTIONTYPE_SLOW" 0 "CONNECTIONTYPE_FAST" ;
VAL_ 1066 VCSEC_TPMSConnectionTypeDesired3 3 "CONNECTIONTYPE_FAST_SLAVE_LATENCY" 2 "CONNECTIONTYPE_UNKNOWN" 1 "CONNECTIONTYPE_SLOW" 0 "CONNECTIONTYPE_FAST" ;
VAL_ 1066 VCSEC_TPMSSensorPresence0 2 "PRESENT" 1 "NOT_PRESENT" 0 "NOT_PAIRED" ;
VAL_ 1066 VCSEC_TPMSSensorPresence1 2 "PRESENT" 1 "NOT_PRESENT" 0 "NOT_PAIRED" ;
VAL_ 1066 VCSEC_TPMSSensorPresence2 2 "PRESENT" 1 "NOT_PRESENT" 0 "NOT_PAIRED" ;
VAL_ 1066 VCSEC_TPMSSensorPresence3 2 "PRESENT" 1 "NOT_PRESENT" 0 "NOT_PAIRED" ;
VAL_ 1817 VCSEC_debug100msIndex 23 "ConnectionBenchmark2" 22 "ConnectionBenchmark1" 21 "ConnectionBenchmark0" 20 "BLEDeviceDebug" 19 "SerialPortDebug" 14 "NNClassifierDebug" 13 "ProtobufDebug" 12 "RoutableDebug" 10 "NIStateRemote" 9 "NIState2" 8 "NIState0" 7 "BLEBondingState" 5 "Mux5" 3 "LastAdvertRSSI" 2 "UHFReceiver" 1 "Mux1" 0 "Mux0" ;
VAL_ 1817 VCSEC_walkAwayLockKeyState 3 "SECURITY_WALKAWAYLOCKING_NO_KEYS_PRESENT" 2 "SECURITY_WALKAWAYLOCKING_KEY_WAIT_FOR_NO_KEYS_PRESENT" 1 "SECURITY_WALKAWAYLOCKING_KEY_STATE_AWAITING_KEY_LEAVING" 0 "SECURITY_WALKAWAYLOCKING_KEY_STATE_IDLE" ;
VAL_ 1817 VCSEC_walkAwayLockState 5 "SECURITY_WALKAWAYLOCKING_STATE_INHIBITED" 4 "SECURITY_WALKAWAYLOCKING_STATE_DISABLED_DUE_TO_KEY_PRESENT" 3 "SECURITY_WALKAWAYLOCKING_STATE_LOCK_DESIRED" 2 "SECURITY_WALKAWAYLOCKING_STATE_WAITING_FOR_KEY_LEAVING" 1 "SECURITY_WALKAWAYLOCKING_STATE_WALK_AWAY_LOCK_ARMING" 0 "SECURITY_WALKAWAYLOCKING_STATE_IDLE" ;
VAL_ 1817 VCSEC_endpointLayout 2 "VCSEC_ENDPOINT_LAYOUT_3" 1 "VCSEC_ENDPOINT_LAYOUT_2" 0 "VCSEC_ENDPOINT_LAYOUT_1" ;
VAL_ 1817 VCSEC_walkUpUnlockState 4 "WALK_UP_UNLOCK_STATE_DISABLED" 3 "WALK_UP_UNLOCK_STATE_UNLOCK_DESIRED" 2 "WALK_UP_UNLOCK_STATE_AWAITING_KEY" 1 "WALK_UP_UNLOCK_STATE_ARMING" 0 "WALK_UP_UNLOCK_STATE_IDLE" ;
VAL_ 1817 VCSEC_pollingReason 13 "POLLINGREASON_MULTIPLE" 12 "POLLINGREASON_AUTOPILOT" 11 "POLLINGREASON_APPROACH_LIGHTING" 10 "POLLINGREASON_AUTO_PRESENT_HANDLES" 9 "POLLINGREASON_AUTORELOCK" 8 "POLLINGREASON_DRIVE_AWAY_CHECK_FOR_KEY" 7 "POLLINGREASON_AUTO_PRESENT_DOOR" 6 "POLLINGREASON_ACCESSORY_RAIL" 5 "POLLINGREASON_WALK_UP_UNLOCK" 4 "POLLINGREASON_WALK_AWAY_LOCK" 3 "POLLINGREASON_PASSIVE_UNLOCK" 2 "POLLINGREASON_PASSIVE_AUTHENTICATION" 1 "POLLINGREASON_IMMOBILIZER" 0 "POLLINGREASON_NONE" ;
VAL_ 1817 VCSEC_thermalDetectState 3 "VCSEC_THERMALDETECTIONSTATE_TRIPPED" 2 "VCSEC_THERMALDETECTIONSTATE_CONFIRMING_THRESHOLD" 1 "VCSEC_THERMALDETECTIONSTATE_MONITORING" 0 "VCSEC_THERMALDETECTIONSTATE_DISABLED" ;
